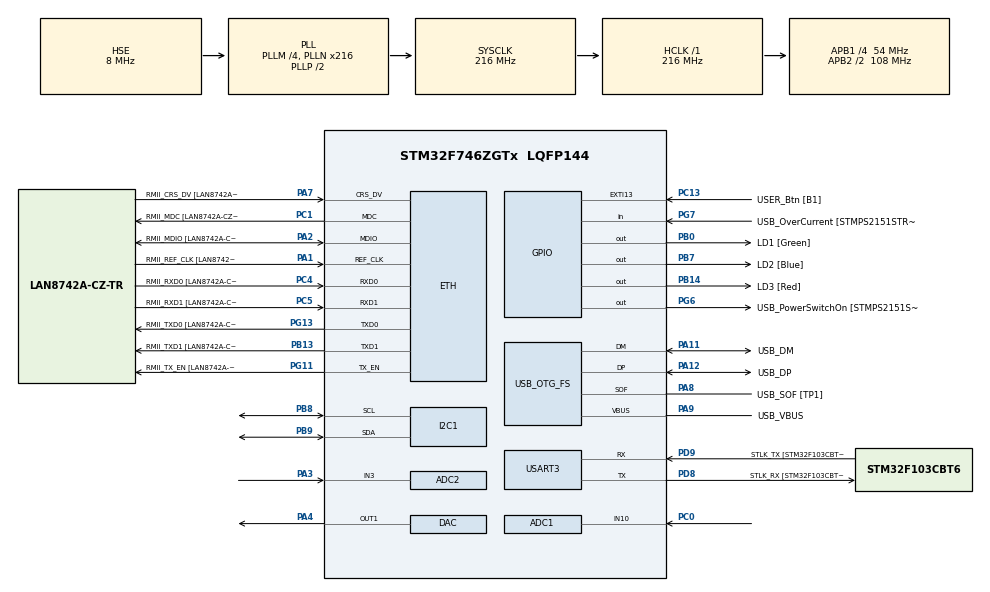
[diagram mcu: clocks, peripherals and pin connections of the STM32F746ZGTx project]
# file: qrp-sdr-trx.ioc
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ADC1.Channel-0\#ChannelRegularConversion=ADC_CHANNEL_10
ADC1.DMAContinuousRequests=ENABLE
ADC1.ExternalTrigConv=ADC_EXTERNALTRIGCONV_T6_TRGO
ADC1.NbrOfConversionFlag=1
ADC1.Rank-0\#ChannelRegularConversion=1
ADC1.SamplingTime-0\#ChannelRegularConversion=ADC_SAMPLETIME_3CYCLES
ADC1.master=1
ADC2.Channel-0\#ChannelRegularConversion=ADC_CHANNEL_3
ADC2.DMAContinuousRequests=ENABLE
ADC2.ExternalTrigConv=ADC_EXTERNALTRIGCONV_T6_TRGO
ADC2.NbrOfConversionFlag=1
ADC2.Rank-0\#ChannelRegularConversion=1
ADC2.SamplingTime-0\#ChannelRegularConversion=ADC_SAMPLETIME_3CYCLES
ADC2.master=1
CORTEX_M7.default_mode_Activation=1
DAC.DAC_Trigger=DAC_TRIGGER_T6_TRGO
DAC.DAC_Trigger_Ch2=DAC_TRIGGER_T6_TRGO
DAC.DAC_OutputBuffer_Ch2=DAC_OUTPUTBUFFER_ENABLE
Dma.ADC1.1.Direction=DMA_PERIPH_TO_MEMORY
Dma.ADC1.1.FIFOMode=DMA_FIFOMODE_DISABLE
Dma.ADC1.1.Instance=DMA2_Stream0
Dma.ADC1.1.MemDataAlignment=DMA_MDATAALIGN_HALFWORD
Dma.ADC1.1.MemInc=DMA_MINC_ENABLE
Dma.ADC1.1.Mode=DMA_CIRCULAR
Dma.ADC1.1.PeriphDataAlignment=DMA_PDATAALIGN_HALFWORD
Dma.ADC1.1.PeriphInc=DMA_PINC_DISABLE
Dma.ADC1.1.Priority=DMA_PRIORITY_HIGH
Dma.ADC2.3.Direction=DMA_PERIPH_TO_MEMORY
Dma.ADC2.3.FIFOMode=DMA_FIFOMODE_DISABLE
Dma.ADC2.3.Instance=DMA2_Stream2
Dma.ADC2.3.MemDataAlignment=DMA_MDATAALIGN_HALFWORD
Dma.ADC2.3.MemInc=DMA_MINC_ENABLE
Dma.ADC2.3.Mode=DMA_CIRCULAR
Dma.ADC2.3.PeriphDataAlignment=DMA_PDATAALIGN_HALFWORD
Dma.ADC2.3.PeriphInc=DMA_PINC_DISABLE
Dma.ADC2.3.Priority=DMA_PRIORITY_HIGH
Dma.DAC1.0.Direction=DMA_MEMORY_TO_PERIPH
Dma.DAC1.0.FIFOMode=DMA_FIFOMODE_DISABLE
Dma.DAC1.0.Instance=DMA1_Stream5
Dma.DAC1.0.MemDataAlignment=DMA_MDATAALIGN_HALFWORD
Dma.DAC1.0.MemInc=DMA_MINC_ENABLE
Dma.DAC1.0.Mode=DMA_CIRCULAR
Dma.DAC1.0.PeriphDataAlignment=DMA_PDATAALIGN_HALFWORD
Dma.DAC1.0.PeriphInc=DMA_PINC_DISABLE
Dma.DAC1.0.Priority=DMA_PRIORITY_HIGH
Dma.DAC2.2.Direction=DMA_MEMORY_TO_PERIPH
Dma.DAC2.2.FIFOMode=DMA_FIFOMODE_DISABLE
Dma.DAC2.2.Instance=DMA1_Stream6
Dma.DAC2.2.MemDataAlignment=DMA_MDATAALIGN_HALFWORD
Dma.DAC2.2.MemInc=DMA_MINC_ENABLE
Dma.DAC2.2.Mode=DMA_CIRCULAR
Dma.DAC2.2.PeriphDataAlignment=DMA_PDATAALIGN_HALFWORD
Dma.DAC2.2.PeriphInc=DMA_PINC_DISABLE
Dma.DAC2.2.Priority=DMA_PRIORITY_HIGH
Dma.Request0=DAC1
Dma.Request1=ADC1
Dma.Request2=DAC2
Dma.Request3=ADC2
ETH.MediaInterface=HAL_ETH_RMII_MODE
ETH.PHY_Name=LAN8742A_PHY_ADDRESS
ETH.PHY_Value=0
ETH.PhyAddress=0
I2C1.Timing=0x20404768
Mcu.Family=STM32F7
Mcu.Name=STM32F746ZGTx
Mcu.Package=LQFP144
NVIC.DMA1_Stream5_IRQn=true\:0\:0\:false\:false\:true\:false\:true\:true
NVIC.DMA1_Stream6_IRQn=true\:0\:0\:false\:false\:true\:false\:true\:true
NVIC.DMA2_Stream0_IRQn=true\:0\:0\:false\:false\:true\:false\:true\:true
NVIC.DMA2_Stream2_IRQn=true\:0\:0\:false\:false\:true\:false\:true\:true
NVIC.PriorityGroup=NVIC_PRIORITYGROUP_4
PA1.GPIO_Label=RMII_REF_CLK [LAN8742A-CZ-TR_REFCLK0]
PA1.Mode=RMII
PA1.Signal=ETH_REF_CLK
PA10.GPIO_Label=USB_ID
PA10.Signal=USB_OTG_FS_ID
PA11.GPIO_Label=USB_DM
PA11.Mode=Device_Only
PA11.Signal=USB_OTG_FS_DM
PA12.GPIO_Label=USB_DP
PA12.Mode=Device_Only
PA12.Signal=USB_OTG_FS_DP
PA13.GPIO_Label=TMS
PA13.Mode=Serial_Wire
PA13.Signal=SYS_JTMS-SWDIO
PA14.GPIO_Label=TCK
PA14.Mode=Serial_Wire
PA14.Signal=SYS_JTCK-SWCLK
PA2.GPIO_Label=RMII_MDIO [LAN8742A-CZ-TR_MDIO]
PA2.Mode=RMII
PA2.Signal=ETH_MDIO
PA3.Signal=ADCx_IN3
PA4.Signal=COMP_DAC1_group
PA5.Signal=DAC_OUT2
PC0.Signal=ADCx_IN10
PA7.GPIO_Label=RMII_CRS_DV [LAN8742A-CZ-TR_CRS_DV]
PA7.Mode=RMII
PA7.Signal=ETH_CRS_DV
PA8.GPIO_Label=USB_SOF [TP1]
PA8.Mode=Activate_SOF_FS
PA8.Signal=USB_OTG_FS_SOF
PA9.GPIO_Label=USB_VBUS
PA9.Mode=Activate_VBUS
PA9.Signal=USB_OTG_FS_VBUS
PB0.GPIO_Label=LD1 [Green]
PB0.Signal=GPIO_Output
PB13.GPIO_Label=RMII_TXD1 [LAN8742A-CZ-TR_TXD1]
PB13.Mode=RMII
PB13.Signal=ETH_TXD1
PB14.GPIO_Label=LD3 [Red]
PB14.Signal=GPIO_Output
PB3.GPIO_Label=SW0
PB3.Signal=SYS_JTDO-SWO
PB7.GPIO_Label=LD2 [Blue]
PB7.Signal=GPIO_Output
PB8.Mode=I2C
PB8.Signal=I2C1_SCL
PB9.Mode=I2C
PB9.Signal=I2C1_SDA
PC1.GPIO_Label=RMII_MDC [LAN8742A-CZ-TR_MDC]
PC1.Mode=RMII
PC1.Signal=ETH_MDC
PC13.GPIO_Label=USER_Btn [B1]
PC13.Signal=GPXTI13
PC14/OSC32_IN.Mode=LSE-External-Oscillator
PC14/OSC32_IN.Signal=RCC_OSC32_IN
PC15/OSC32_OUT.Mode=LSE-External-Oscillator
PC15/OSC32_OUT.Signal=RCC_OSC32_OUT
PC4.GPIO_Label=RMII_RXD0 [LAN8742A-CZ-TR_RXD0]
PC4.Mode=RMII
PC4.Signal=ETH_RXD0
PC5.GPIO_Label=RMII_RXD1 [LAN8742A-CZ-TR_RXD1]
PC5.Mode=RMII
PC5.Signal=ETH_RXD1
PD8.GPIO_Label=STLK_RX [STM32F103CBT6_PA3]
PD8.GPIO_PuPd=GPIO_PULLUP
PD8.Mode=Asynchronous
PD8.Signal=USART3_TX
PD9.GPIO_Label=STLK_TX [STM32F103CBT6_PA2]
PD9.GPIO_PuPd=GPIO_PULLUP
PD9.Mode=Asynchronous
PD9.Signal=USART3_RX
PG11.GPIO_Label=RMII_TX_EN [LAN8742A-CZ-TR_TXEN]
PG11.Mode=RMII
PG11.Signal=ETH_TX_EN
PG13.GPIO_Label=RMII_TXD0 [LAN8742A-CZ-TR_TXD0]
PG13.Mode=RMII
PG13.Signal=ETH_TXD0
PG6.GPIO_Label=USB_PowerSwitchOn [STMPS2151STR_EN]
PG6.Signal=GPIO_Output
PG7.GPIO_Label=USB_OverCurrent [STMPS2151STR_FAULT]
PG7.Signal=GPIO_Input
PH0/OSC_IN.GPIO_Label=MCO [STM32F103CBT6_PA8]
PH0/OSC_IN.Mode=HSE-External-Oscillator
PH0/OSC_IN.Signal=RCC_OSC_IN
PH1/OSC_OUT.Mode=HSE-External-Oscillator
PH1/OSC_OUT.Signal=RCC_OSC_OUT
ProjectManager.HeapSize=0x200
ProjectManager.StackSize=0x400
ProjectManager.TargetToolchain=Makefile
RCC.48MHZClocksFreq_Value=24000000
RCC.AHBFreq_Value=216000000
RCC.APB1CLKDivider=RCC_HCLK_DIV4
RCC.APB1Freq_Value=54000000
RCC.APB1TimFreq_Value=108000000
RCC.APB2CLKDivider=RCC_HCLK_DIV2
RCC.APB2Freq_Value=108000000
RCC.APB2TimFreq_Value=216000000
RCC.CortexFreq_Value=216000000
RCC.HCLKFreq_Value=216000000
RCC.HSE_VALUE=8000000
RCC.HSI_VALUE=16000000
RCC.PLL48CLockSelection=RCC_CLK48SOURCE_PLLSAIP
RCC.PLLM=4
RCC.PLLMUL=RCC_PLL_MUL9
RCC.PLLN=216
RCC.PLLQ=3
RCC.PLLSAIP=RCC_PLLSAIP_DIV8
RCC.PRESCALERUSB=RCC_USBCLKSOURCE_PLL_DIV1_5
RCC.SYSCLKFreq_VALUE=216000000
RCC.SYSCLKSource=RCC_SYSCLKSOURCE_PLLCLK
RCC.SYSCLKSourceVirtual=RCC_SYSCLKSOURCE_PLLCLK
RCC.USBFreq_Value=48000000
RCC.VCOOutputFreq_Value=432000000
SH.ADCx_IN3.0=ADC2_IN3,IN3
SH.ADCx_IN10.0=ADC1_IN10,IN10
SH.COMP_DAC1_group.0=DAC_OUT1,DAC_OUT1
TIM6.Period=49
TIM6.Prescaler=44
TIM6.TIM_MasterOutputTrigger=TIM_TRGO_UPDATE
USART3.VirtualMode-Asynchronous=VM_ASYNC
USB_OTG_FS.VirtualMode=Device_Only
VP_TIM6_VS_ClockSourceINT.Mode=Enable_Timer
board=NUCLEO-F746ZG

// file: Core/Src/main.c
/* USER CODE BEGIN Header */
/**
  ******************************************************************************
  * @file           : main.c
  * @brief          : Main program body
  ******************************************************************************
  * @attention
  *
  * Copyright (c) 2026 STMicroelectronics.
  * All rights reserved.
  *
  * This software is licensed under terms that can be found in the LICENSE file
  * in the root directory of this software component.
  * If no LICENSE file comes with this software, it is provided AS-IS.
  *
  ******************************************************************************
  */
/* USER CODE END Header */
#include "main.h"
#include "string.h"
#include <stdlib.h>

/* USER CODE BEGIN Includes */
#include "stm32f7xx.h"      // <-- MÅ være først
#include "arm_math.h"       // <-- CMSIS-DSP
#include "dsp.h"            // <-- dine DSP-typer
#include "freedv_chain.h"   // <-- FreeDV 1600 RX-kjede
#include "oled.h"
#include "encoder.h"
#include "buttons.h"
#include "hmi.h"
#include "cw_paddle.h"
#include "usb_device.h"
#include "usbd_audio_duplex.h"
#include <math.h>
#include <stdio.h>

/* USER CODE END Includes */

/* USER CODE BEGIN PM */
#define TWO_PI 6.28318530718f
/*
 * Block size is per mode, so the buffers are allocated for the largest case and
 * the DMA is restarted with the size the current mode wants.
 *
 * FreeDV: half a buffer is 1920 samples = 40 ms, and 1920/6 = 320, which is
 * exactly one FDMDV frame. That makes every block cost the same instead of
 * alternating cheap/expensive, which is what it takes to stay real time.
 *
 * FreeDV 2400B: 96 bits at 4800 baud, so 1920 samples at 48 kHz, the same 40 ms
 * as 1600. Its modem is already at 48 kHz, so unlike 1600 there is no
 * resampling on the way in.
 *
 * Analog: 256 samples = 5.3 ms. SSB, AM and NBFM do not care much, but CW
 * break-in does, and 40 ms of round trip delay is very audible on a key.
 */
#define BLOCK_SIZE_MAX     3840
#define BLOCK_SIZE_FREEDV  3840
#define BLOCK_SIZE_2400B   3840
#define BLOCK_SIZE_700D    3840
#define BLOCK_SIZE_700E    3840
#define BLOCK_SIZE_ANALOG   512

// Active size, swapped by radio_set_mode(). Buffers stay BLOCK_SIZE_MAX.
static volatile uint32_t block_size = BLOCK_SIZE_FREEDV;
/* USER CODE END PM */

#if defined ( __ICCARM__ ) /*!< IAR Compiler */
#pragma location=0x2004c000
ETH_DMADescTypeDef  DMARxDscrTab[ETH_RX_DESC_CNT]; /* Ethernet Rx DMA Descriptors */
#pragma location=0x2004c0a0
ETH_DMADescTypeDef  DMATxDscrTab[ETH_TX_DESC_CNT]; /* Ethernet Tx DMA Descriptors */

#elif defined ( __CC_ARM )  /* MDK ARM Compiler */

__attribute__((at(0x2004c000))) ETH_DMADescTypeDef  DMARxDscrTab[ETH_RX_DESC_CNT]; /* Ethernet Rx DMA Descriptors */
__attribute__((at(0x2004c0a0))) ETH_DMADescTypeDef  DMATxDscrTab[ETH_TX_DESC_CNT]; /* Ethernet Tx DMA Descriptors */

#elif defined ( __GNUC__ ) /* GNU Compiler */

ETH_DMADescTypeDef DMARxDscrTab[ETH_RX_DESC_CNT] __attribute__((section(".RxDecripSection"))); /* Ethernet Rx DMA Descriptors */
ETH_DMADescTypeDef DMATxDscrTab[ETH_TX_DESC_CNT] __attribute__((section(".TxDecripSection")));   /* Ethernet Tx DMA Descriptors */
#endif

ETH_TxPacketConfig TxConfig;

ADC_HandleTypeDef hadc1;   /* RX: IF in, PC0 */
DMA_HandleTypeDef hdma_adc1;

ADC_HandleTypeDef hadc2;   /* TX: mic in, PA3 */
DMA_HandleTypeDef hdma_adc2;

DAC_HandleTypeDef hdac;
DMA_HandleTypeDef hdma_dac1;   /* RX: audio out, PA4 (DAC_OUT1) */
DMA_HandleTypeDef hdma_dac2;   /* TX: IF out, PA5 (DAC_OUT2) */

ETH_HandleTypeDef heth;

I2C_HandleTypeDef hi2c1;

TIM_HandleTypeDef htim6;

UART_HandleTypeDef huart3;

PCD_HandleTypeDef hpcd_USB_OTG_FS;

/* USER CODE BEGIN PV */

/*
 * The ADC DMA buffer doubles as the input FIFO for the buffered modes, so it
 * is deeper than one block: five blocks, i.e. 200 ms at 48 kHz. The DMA writes
 * into it continuously and the DSP reads behind, which decouples processing
 * time from the block period without a second copy of the data. Halfword
 * samples because the ADC is 12-bit.
 */
#define ADC_RING_BLOCKS 4
#define ADC_RING_LEN    (ADC_RING_BLOCKS * (BLOCK_SIZE_MAX / 2))

/*
 * Transmit DAC buffer, three blocks deep. In the buffered (FreeDV) modes the
 * DMA plays through it continuously while the main loop encodes and fills
 * ahead, so a 53 ms OFDM encode draws down the cushion instead of stalling the
 * output. The analog modes keep using the first block_size of it as a simple
 * double buffer.
 */
#define DAC_RING_BLOCKS 4
#define DAC_RING_LEN    (DAC_RING_BLOCKS * (BLOCK_SIZE_MAX / 2))

uint16_t dac_buffer[DAC_RING_LEN] = {0};
uint16_t adc_buffer[ADC_RING_LEN] = {0};

// CW sidetone: DAC_OUT1/PA4 (the RX speaker output) doubles as the TX
// sidetone during CW, same as [[cw-design-decisions]] always intended -
// keying is heard through the speaker/phones while DAC_OUT2 carries the
// actual IF out. Only driven (DMA started) when tx_active && MODE_CW; see
// audio_dma_start(). Sized for CW's block size, not the deep DAC_RING_LEN
// ring - CW is always the shallow non-buffered path (mode_cfg[MODE_CW] is
// BLOCK_SIZE_ANALOG, buffered=0), so anything bigger is just wasted static
// RAM, at exactly the size that matters for the heap FreeDV 700D needs.
uint16_t sidetone_buffer[BLOCK_SIZE_ANALOG] = {0};

volatile uint8_t block_ready = 0; // 0: no block ready, 1: first half ready, 2: second half ready
volatile uint8_t dac_block_processing = 0; // 0: not processing, 1: processing

int freedv_ok = 0;          // set once freedv_chain_init() has succeeded

// RX telemetry, printed once a second over the ST-Link VCP
volatile uint32_t rx_blocks = 0;   // blocks through process_block()
volatile float    rx_peak   = 0.0f; // peak |audio| at the modem input
volatile float    rx_rms    = 0.0f; // rms of the same, to judge peak/rms
volatile float    rx_env_min = 0.0f; // AM: smallest envelope value in the block
volatile float    rx_env_avg = 0.0f; // AM: mean envelope, i.e. the carrier level
volatile float    rx_adc_peak = 0.0f; // peak |ADC| before any filtering
volatile uint32_t rx_cycles_max = 0;  // worst-case cycles for one block
volatile uint32_t rx_fdv_cycles_max = 0; // worst-case cycles inside the FreeDV chain
volatile uint32_t rx_adc_cycles = 0;     // TX: worst-case encode cycles
volatile uint32_t tx_cushion_min = 999999; // TX: smallest DAC lead, in samples
static   uint32_t last_report = 0;
static   int      debug_on    = 0;   // continuous telemetry print, off by default

// DWT cycle counter, used to measure how much of each block period the DSP
// actually consumes. One block is block_size/2 samples at 48 kHz.
static void cyclecount_init(void)
{
    CoreDebug->DEMCR |= CoreDebug_DEMCR_TRCENA_Msk;

    // Cortex-M7 gates the DWT registers behind the lock access register; without
    // this CYCCNT stays at 0 and every measurement reads back as zero.
    DWT->LAR = 0xC5ACCE55;

    DWT->CYCCNT = 0;
    DWT->CTRL  |= DWT_CTRL_CYCCNTENA_Msk;
}
nco_t nco;

// NCO for IF-mixing
nco_t nco_if;

// Pre-demod IF-filter (kompleks, men vi bruker samme koeff for I og Q)
arm_fir_instance_f32 pre_demod_filter;

/*

FIR filter designed with
http://t-filter.appspot.com

sampling frequency: 48000 Hz

* 0 Hz - 4000 Hz
  gain = 1
  desired ripple = 0.1 dB
  actual ripple = 0.06811726811384558 dB

* 6000 Hz - 24000 Hz
  gain = 0
  desired attenuation = -60 dB
  actual attenuation = -60.68801081580469 dB

*/

#define PRE_DEMOD_TAPS 73

static float pre_demod_coeffs[PRE_DEMOD_TAPS] = {
  -0.0004930375303321366,
  0.0001064813438661428,
  0.0005748457570259578,
  0.0011898445128213748,
  0.0016502280581233504,
  0.001605207031383133,
  0.000831446560674343,
  -0.0005973708354363059,
  -0.002228627696676951,
  -0.0033377455060532744,
  -0.0032076016149152073,
  -0.0014978471407907723,
  0.001459284866735388,
  0.004620535335059582,
  0.00653528877009168,
  0.0059370991846072535,
  0.00240691382833557,
  -0.003197318174051976,
  -0.008810233649088216,
  -0.0118211865758766,
  -0.010154929160148466,
  -0.003367069515417546,
  0.006744477803887592,
  0.016400388788851774,
  0.021048898446146783,
  0.017199001020187076,
  0.0042202354750242735,
  -0.014651068016007818,
  -0.032657469215897225,
  -0.04131750763191529,
  -0.03320662673344374,
  -0.004808839248635039,
  0.04161063532888555,
  0.09790380688954856,
  0.1519161665559878,
  0.1908448312364271,
  0.20501884795915196,
  0.1908448312364271,
  0.1519161665559878,
  0.09790380688954856,
  0.04161063532888555,
  -0.004808839248635039,
  -0.03320662673344374,
  -0.04131750763191529,
  -0.032657469215897225,
  -0.014651068016007818,
  0.0042202354750242735,
  0.017199001020187076,
  0.021048898446146783,
  0.016400388788851774,
  0.006744477803887592,
  -0.003367069515417546,
  -0.010154929160148466,
  -0.0118211865758766,
  -0.008810233649088216,
  -0.003197318174051976,
  0.00240691382833557,
  0.0059370991846072535,
  0.00653528877009168,
  0.004620535335059582,
  0.001459284866735388,
  -0.0014978471407907723,
  -0.0032076016149152073,
  -0.0033377455060532744,
  -0.002228627696676951,
  -0.0005973708354363059,
  0.000831446560674343,
  0.001605207031383133,
  0.0016502280581233504,
  0.0011898445128213748,
  0.0005748457570259578,
  0.0001064813438661428,
  -0.0004930375303321366
};

/*
 * Scratch shared by ssb_process_block() and nbfm_process_block().
 *
 * process_block() dispatches to exactly one of them, so they are never live at
 * the same time and there is no reason for each to hold its own statics. Both
 * also used to over-allocate: the interleaved buffers only ever index up to
 * 2*n, and the real buffers up to n, where n = BLOCK_SIZE/2.
 *
 * Layout is 10*n floats, which is what nbfm needs (4 real + 3 interleaved);
 * ssb uses 9*n of it. Keeping these separate is what made BLOCK_SIZE 3840
 * overflow RAM.
 */
#define SCRATCH_N (BLOCK_SIZE_MAX / 2)
static float dsp_scratch[10 * SCRATCH_N];

/*
 * CW audio filter: three identical biquad band-pass sections at the tone pitch.
 *
 * Biquads rather than a FIR because pitch and bandwidth are meant to become
 * front panel controls. Retuning this is five coefficients; a FIR with the
 * same skirts would be hundreds of taps to redesign on every turn of a knob.
 * cw_bpf_retune() below is that front-panel-control path, wired up 2026-08-03.
 *
 * Each section is deliberately wider than the target: cascading three narrows
 * the result, so Q 1.42 per section gives about 250 Hz overall. Going much
 * below that starts to ring and smears the elements at speed, which reads
 * worse than a wider filter.
 */
#define CW_PITCH_DEFAULT_HZ  700.0f
#define CW_PITCH_MIN_HZ      300.0f
#define CW_PITCH_MAX_HZ     1000.0f
#define CW_FILTER_Q           1.42f
#define CW_STAGES     3

// Runtime pitch: also what the TX carrier offsets from the IF centre by
// (see cw_tx_restart()), so RX filter and TX sidetone stay one linked
// setting rather than drifting apart - the design principle from
// [[cw-design-decisions]].
float cw_pitch_hz = CW_PITCH_DEFAULT_HZ;

// CMSIS's biquad init stores the pointer it's given rather than copying, so
// this has to be static storage, not a stack buffer computed on the fly.
static float cw_coeffs_runtime[5 * CW_STAGES];

arm_biquad_casd_df1_inst_f32 cw_bpf;
static float cw_state[4 * CW_STAGES];

/*
 * (Re)design the CW band-pass filter for a new centre frequency, RBJ
 * "constant skirt gain" band-pass biquad, reverse-derived to match this
 * project's original fixed-700 Hz coefficients (Q 1.42, confirmed by
 * working backward from them to within rounding). Same 5 coefficients in
 * all three cascaded stages, same as the fixed table this replaces.
 */
static void cw_bpf_retune(float pitch_hz)
{
    float w0    = TWO_PI * pitch_hz / 48000.0f;
    float alpha = sinf(w0) / (2.0f * CW_FILTER_Q);
    float a0    = 1.0f + alpha;
    float cosw0 = cosf(w0);

    float b0 =  alpha / a0;
    float b2 = -alpha / a0;
    float a1 =  (2.0f * cosw0) / a0;   /* CMSIS df1 sign convention */
    float a2 = -(1.0f - alpha) / a0;

    for (int s = 0; s < CW_STAGES; s++)
    {
        cw_coeffs_runtime[5*s + 0] = b0;
        cw_coeffs_runtime[5*s + 1] = 0.0f;
        cw_coeffs_runtime[5*s + 2] = b2;
        cw_coeffs_runtime[5*s + 3] = a1;
        cw_coeffs_runtime[5*s + 4] = a2;
    }

    arm_biquad_cascade_df1_init_f32(&cw_bpf, CW_STAGES, cw_coeffs_runtime, cw_state);
}

/* Clamp and apply a new CW pitch - called from the HMI (Function -> CW
   pitch -> encoder) and available for the console later if wanted. Retunes
   immediately regardless of MODE; harmless when not in CW, since cw_bpf
   just sits unused until MODE_CW reads it. */
void cw_set_pitch(float hz)
{
    if (hz < CW_PITCH_MIN_HZ) hz = CW_PITCH_MIN_HZ;
    if (hz > CW_PITCH_MAX_HZ) hz = CW_PITCH_MAX_HZ;
    cw_pitch_hz = hz;
    cw_bpf_retune(cw_pitch_hz);
}

arm_fir_instance_f32 pre_fm_I;
arm_fir_instance_f32 pre_fm_Q;

static float pre_fm_state_I[PRE_DEMOD_TAPS + BLOCK_SIZE_MAX/2];
static float pre_fm_state_Q[PRE_DEMOD_TAPS + BLOCK_SIZE_MAX/2];

/* USER CODE END PV */

void SystemClock_Config(void);
static void MPU_Config(void);
static void MX_GPIO_Init(void);
static void MX_DMA_Init(void);
static void MX_ETH_Init(void);
static void MX_I2C1_Init(void);
static void MX_USART3_UART_Init(void);
static void MX_USB_OTG_FS_PCD_Init(void);
static void MX_DAC_Init(void);
static void MX_TIM6_Init(void);
static void MX_ADC1_Init(void);
static void MX_ADC2_Init(void);

/* USER CODE BEGIN 0 */

/*
 * USART3 is wired to the ST-Link virtual COM port (/dev/ttyACM0), 115200 8N1.
 *
 * Queued rather than sent with HAL_UART_Transmit, which blocks: a 123 character
 * telemetry line takes 10.7 ms at 115200, and the analog block period is
 * 5.3 ms, so every report used to cost two blocks of audio. Here uart_puts()
 * only appends and uart_pump() moves one byte per main loop pass, which is
 * ample when the loop turns over hundreds of thousands of times a second.
 */
#define TX_RING 512   /* power of two */

static char              tx_ring[TX_RING];
static volatile uint16_t tx_wr, tx_rd;

static void uart_pump(void)
{
    if (tx_rd != tx_wr && (huart3.Instance->ISR & USART_ISR_TXE))
        huart3.Instance->TDR = tx_ring[tx_rd++ & (TX_RING - 1)];
}

/* uart_pump() above only moves one byte per main-loop pass - fine for
   telemetry, but useless for a diagnostic printed right before a crash that
   never returns to the main loop. Blocks until the whole ring is actually
   on the wire, not just queued. Exported for codec2_alloc_report_fail() in
   freedv_chain.c, the one caller that needs a guarantee, not a best effort. */
void uart_flush_blocking(void)
{
    while (tx_rd != tx_wr)
    {
        while (!(huart3.Instance->ISR & USART_ISR_TXE)) { }
        huart3.Instance->TDR = tx_ring[tx_rd++ & (TX_RING - 1)];
    }
}

void uart_puts(const char *s)
{
    while (*s)
    {
        /* Only ever blocks if the queue backs up, which startup can do. */
        while ((uint16_t)(tx_wr - tx_rd) >= TX_RING)
            uart_pump();

        tx_ring[tx_wr++ & (TX_RING - 1)] = *s++;
    }
}

// Integer-only formatting on purpose: printf("%f") needs -u _printf_float,
// which nano.specs leaves out.
static void uart_kv(const char *key, int value)
{
    char buf[48];
    char *p = buf;
    int   n = value;
    int   digits = 0;
    char  tmp[12];

    while (*key)
        *p++ = *key++;
    *p++ = '=';

    if (n < 0) { *p++ = '-'; n = -n; }
    do { tmp[digits++] = '0' + (n % 10); n /= 10; } while (n);
    while (digits)
        *p++ = tmp[--digits];

    *p++ = ' ';
    *p   = '\0';

    uart_puts(buf);
}

// If block_ready is still set when the next half completes, the main loop did
// not keep up and a block of samples is lost. FreeDV cannot tolerate that: the
// modem needs an unbroken sample stream to hold sync.
volatile uint32_t rx_overruns = 0;

/*
 * Read position into the ADC ring. The DMA controller is the writer and its
 * position is the transfer counter, so nothing has to be tracked in an ISR.
 * The ring is a whole number of blocks, so a block read never wraps.
 *
 * Half duplex, so exactly one ADC and one DAC channel is ever running:
 * hadc1/DAC_OUT1 (IF in / audio out) on RX, hadc2/DAC_OUT2 (mic in / IF out)
 * on TX. tx_active picks which pair's DMA position is live.
 */
extern volatile int tx_active;

static uint32_t adc_rd;

static uint32_t adc_dma_pos(void)
{
    ADC_HandleTypeDef *adc = tx_active ? &hadc2 : &hadc1;
    return ADC_RING_LEN - __HAL_DMA_GET_COUNTER(adc->DMA_Handle);
}

static uint32_t dac_dma_pos(void)
{
    DMA_HandleTypeDef *dma = tx_active ? hdac.DMA_Handle2 : hdac.DMA_Handle1;
    return DAC_RING_LEN - __HAL_DMA_GET_COUNTER(dma);
}

static uint32_t adc_avail(void)
{
    uint32_t w = adc_dma_pos();
    return (w >= adc_rd) ? (w - adc_rd) : (ADC_RING_LEN - adc_rd + w);
}

extern int MODE;                 /* defined further down, with the mode list */
int mode_is_buffered(int mode);

void HAL_ADC_ConvHalfCpltCallback(ADC_HandleTypeDef *hadc)
{
    if (mode_is_buffered(MODE)) return;   /* the DSP reads the ring directly */

    if (block_ready) rx_overruns++;
    block_ready = 1;
}

void HAL_ADC_ConvCpltCallback(ADC_HandleTypeDef *hadc)
{
    if (mode_is_buffered(MODE)) return;   /* the DSP reads the ring directly */

    if (block_ready) rx_overruns++;
    block_ready = 2;
}

void HAL_DAC_ConvHalfCpltCallbackCh1(DAC_HandleTypeDef *hdac)
{
    // DAC half conversion complete callback (channel 1)
    // You can add code here if needed
    dac_block_processing = 1;
}

void HAL_DAC_ConvCpltCallbackCh1(DAC_HandleTypeDef *hdac)
{
    // DAC conversion complete callback (channel 1)
    // You can add code here if needed
    dac_block_processing = 2;
}

/*
 * Channel 2 (TX IF out) mirrors channel 1: dac_block_processing is what
 * paces tx_process_block() in the main loop, and on TX it is channel 2 that
 * is actually running the DMA, not channel 1.
 */
void HAL_DACEx_ConvHalfCpltCallbackCh2(DAC_HandleTypeDef *hdac)
{
    dac_block_processing = 1;
}

void HAL_DACEx_ConvCpltCallbackCh2(DAC_HandleTypeDef *hdac)
{
    dac_block_processing = 2;
}

/*
//Hilbert filter for SSB
#define HILBERT_TAPS 63

static float hilbert_coeffs[HILBERT_TAPS] = {
    -0.0041, -0.0037, -0.0028, -0.0014, 0.0004, 0.0025, 0.0047,
    0.0067, 0.0082, 0.0089, 0.0086, 0.0071, 0.0044, 0.0007,
    -0.0034, -0.0076, -0.0114, -0.0143, -0.0158, -0.0156,
    -0.0135, -0.0096, -0.0043, 0.0020, 0.0087, 0.0151,
    0.0204, 0.0239, 0.0251, 0.0239, 0.0204, 0.0151,
    0.0087, 0.0020, -0.0043, -0.0096, -0.0135, -0.0156,
    -0.0158, -0.0143, -0.0114, -0.0076, -0.0034, 0.0007,
    0.0044, 0.0071, 0.0086, 0.0089, 0.0082, 0.0067,
    0.0047, 0.0025, 0.0004, -0.0014, -0.0028, -0.0037,
    -0.0041
};
*/

//Hilbert filter for NBFM
/*

FIR filter designed with
http://t-filter.appspot.com

sampling frequency: 48000 Hz

* 0 Hz - 6000 Hz
  gain = 0
  desired attenuation = -60 dB
  actual attenuation = -50.41488654693752 dB

* 8000 Hz - 16000 Hz
  gain = 1
  desired ripple = 5 dB
  actual ripple = 15.449541453020096 dB

* 18000 Hz - 24000 Hz
  gain = 0
  desired attenuation = -60 dB
  actual attenuation = -50.41488654693752 dB

*/

#define HILBERT_TAPS 17

static float hilbert_coeffs[HILBERT_TAPS] = {
  0.02352204878641468,
  -7.964549159078516e-16,
  -0.094806149454076,
  5.916427478655016e-16,
  0.21352320600109478,
  -7.4996177568773785e-16,
  -0.3325693585500034,
  4.3317065620714974e-17,
  0.3830170947566392,
  4.3317065620714974e-17,
  -0.3325693585500034,
  -7.4996177568773785e-16,
  0.21352320600109478,
  5.916427478655016e-16,
  -0.094806149454076,
  -7.964549159078516e-16,
  0.02352204878641468
};

static float hilbert_state[HILBERT_TAPS + BLOCK_SIZE_MAX/2];
arm_fir_instance_f32 hilbert;

#define IF_TAPS 101

static float if_coeffs[101] = {
    -0.0003, -0.0004, -0.0005, -0.0006, -0.0007, -0.0008,
    -0.0009, -0.0010, -0.0011, -0.0012, -0.0013, -0.0014,
    -0.0015, -0.0016, -0.0017, -0.0018, -0.0019, -0.0020,
    -0.0021, -0.0022, -0.0023, -0.0024, -0.0025, -0.0026,
    -0.0027, -0.0028, -0.0029, -0.0030, -0.0031, -0.0032,
    -0.0033, -0.0034, -0.0035, -0.0036, -0.0037, -0.0038,
    -0.0039, -0.0040, -0.0041, -0.0042, -0.0043, -0.0044,
    -0.0045, -0.0046, -0.0047, -0.0048, -0.0049, -0.0050,
    0.9950,
    -0.0050, -0.0049, -0.0048, -0.0047, -0.0046, -0.0045,
    -0.0044, -0.0043, -0.0042, -0.0041, -0.0040, -0.0039,
    -0.0038, -0.0037, -0.0036, -0.0035, -0.0034, -0.0033,
    -0.0032, -0.0031, -0.0030, -0.0029, -0.0028, -0.0027,
    -0.0026, -0.0025, -0.0024, -0.0023, -0.0022, -0.0021,
    -0.0020, -0.0019, -0.0018, -0.0017, -0.0016, -0.0015,
    -0.0014, -0.0013, -0.0012, -0.0011, -0.0010, -0.0009,
    -0.0008, -0.0007, -0.0006, -0.0005, -0.0004, -0.0003
};

static float if_state[IF_TAPS + BLOCK_SIZE_MAX/2];
arm_fir_instance_f32 pre_demod_filter;

#define AUDIO_TAPS 63

static float audio_lpf_coeffs[AUDIO_TAPS] = {
    // 3 kHz LPF, 48 kHz fs, Hamming window
    -0.0007, -0.0010, -0.0013, -0.0016, -0.0019, -0.0022,
    -0.0025, -0.0028, -0.0031, -0.0034, -0.0037, -0.0040,
    -0.0043, -0.0046, -0.0049, -0.0052, -0.0055, -0.0058,
    -0.0061, -0.0064, -0.0067, -0.0070, -0.0073, -0.0076,
    -0.0079, -0.0082, -0.0085, -0.0088, -0.0091, -0.0094,
    0.9900,
    -0.0094, -0.0091, -0.0088, -0.0085, -0.0082, -0.0079,
    -0.0076, -0.0073, -0.0070, -0.0067, -0.0064, -0.0061,
    -0.0058, -0.0055, -0.0052, -0.0049, -0.0046, -0.0043,
    -0.0040, -0.0037, -0.0034, -0.0031, -0.0028, -0.0025,
    -0.0022, -0.0019, -0.0016, -0.0013, -0.0010, -0.0007
};

static float audio_state[AUDIO_TAPS + BLOCK_SIZE_ANALOG/2];
arm_fir_instance_f32 audio_lpf;

#define MODE_NBFM 0
#define MODE_USB  1
#define MODE_LSB  2
#define MODE_FREEDV 3   // FreeDV 1600, received as USB
#define MODE_FREEDV_2400B 4  // FreeDV 2400B, through a normal FM audio path
#define MODE_FREEDV_700D  5  // FreeDV 700D, OFDM + LDPC on SSB for weak signals
#define MODE_FREEDV_700E  6  // FreeDV 700E, shorter frame than 700D, faster reacquire
#define MODE_AM           7  // AM, envelope detection off the complex baseband
#define MODE_CW           8  // CW, SSB demod into a narrow filter at the tone pitch

int MODE = MODE_USB;  // default mode

/*
 * Fill an interleaved cos/sin buffer for the IF mixer.
 *
 * Recursive phasor rotation rather than cosf()/sinf() per sample: two libm
 * calls per sample was one of the larger costs in the block. Magnitude drifts
 * slowly, so it is renormalised once per call instead of per sample.
 */
static void nco_block_iq(float *NCO_buf, int n)
{
    static float osc_re = 1.0f, osc_im = 0.0f;
    static float step_re = 1.0f, step_im = 0.0f;
    static float step_dphi = 0.0f;

    if (step_dphi != nco.dphi)
    {
        step_dphi = nco.dphi;
        step_re   = cosf(nco.dphi);
        step_im   = sinf(nco.dphi);
    }

    for (int i = 0; i < n; i++)
    {
        NCO_buf[2*i + 0] = osc_re;
        NCO_buf[2*i + 1] = osc_im;

        float nre = osc_re * step_re - osc_im * step_im;
        float nim = osc_re * step_im + osc_im * step_re;

        osc_re = nre;
        osc_im = nim;
    }

    float mag2 = osc_re * osc_re + osc_im * osc_im;
    float g    = 1.5f - 0.5f * mag2;   // one Newton step toward 1/sqrt(mag2)

    osc_re *= g;
    osc_im *= g;
}

void ssb_process_block(const uint16_t *in, uint16_t *out, int n)
{
    // Carved out of the shared scratch pool; see dsp_scratch above.
    float *I_buf     = &dsp_scratch[0 * SCRATCH_N];
    float *Q_buf     = &dsp_scratch[1 * SCRATCH_N];
    float *audio_buf = &dsp_scratch[2 * SCRATCH_N];

    float *IQ_in     = &dsp_scratch[3 * SCRATCH_N];   // interleaved I/Q,   2n
    float *NCO_buf   = &dsp_scratch[5 * SCRATCH_N];   // interleaved cos/sin, 2n
    float *IQ_mix    = &dsp_scratch[7 * SCRATCH_N];   // interleaved I/Q,   2n
    float *ssb_raw   = &dsp_scratch[9 * SCRATCH_N];   // FreeDV fallback audio, see MODE_FREEDV below

    // ---------------------------------------------------------
    // 1) ADC → normalisert I
    // ---------------------------------------------------------
    float adc_peak = 0.0f;

    for (int i = 0; i < n; i++)
    {
        uint32_t raw = in[i] & 0x0FFF;
        I_buf[i] = ((float)raw - 2048.0f) / 2048.0f;

        float a = fabsf(I_buf[i]);
        if (a > adc_peak) adc_peak = a;
    }

    rx_adc_peak = adc_peak;

    // ---------------------------------------------------------
    // 2) Hilbert → Q (for SSB og FM)
    // ---------------------------------------------------------
    arm_fir_f32(&hilbert, I_buf, Q_buf, n);

    // ---------------------------------------------------------
    // 3) Lag interleaved I/Q
    // ---------------------------------------------------------
    for (int i = 0; i < n; i++)
    {
        IQ_in[2*i + 0] = I_buf[i];
        IQ_in[2*i + 1] = Q_buf[i];
    }

    // ---------------------------------------------------------
    // 4) NCO → interleaved cos/sin
    // ---------------------------------------------------------
    nco_block_iq(NCO_buf, n);

    // ---------------------------------------------------------
    // 5) Kompleks mixing
    // ---------------------------------------------------------
    arm_cmplx_mult_cmplx_f32(IQ_in, NCO_buf, IQ_mix, n);

    // ---------------------------------------------------------
    // 6) Splitt ut I/Q etter mixing
    // ---------------------------------------------------------
    for (int i = 0; i < n; i++)
    {
        I_buf[i] = IQ_mix[2*i + 0];
        Q_buf[i] = IQ_mix[2*i + 1];
    }

    // ---------------------------------------------------------
    // 7) Pre-demod IF-filter
    // ---------------------------------------------------------
    arm_fir_f32(&pre_fm_I, I_buf, I_buf, n);
    arm_fir_f32(&pre_fm_Q, Q_buf, Q_buf, n);

    // ---------------------------------------------------------
    // 8) MODE-basert demod
    // ---------------------------------------------------------
    if(MODE == MODE_USB)
    {
        // USB = I - Q  (swapped to match how the sideband lands on the air
        // after the up-conversion, confirmed against an FT-857D)
        for (int i = 0; i < n; i++)
            audio_buf[i] = I_buf[i] - Q_buf[i];

        /* Post-demod level, same pattern as the CW branch below - this is
           what the HMI's S-meter reads (hmi.c), so it needs to reflect the
           tuned signal, not just the raw pre-mix ADC swing. */
        float peak = 0.0f, sumsq = 0.0f;
        for (int i = 0; i < n; i++)
        {
            float a = fabsf(audio_buf[i]);
            if (a > peak) peak = a;
            sumsq += audio_buf[i] * audio_buf[i];
        }
        rx_peak = peak;
        rx_rms  = sqrtf(sumsq / (float)n);
        rx_blocks++;
    }
    else if (MODE == MODE_LSB)
    {
        // LSB = I + Q
        for (int i = 0; i < n; i++)
            audio_buf[i] = I_buf[i] + Q_buf[i];

        /* Same reasoning as MODE_USB above. */
        float peak = 0.0f, sumsq = 0.0f;
        for (int i = 0; i < n; i++)
        {
            float a = fabsf(audio_buf[i]);
            if (a > peak) peak = a;
            sumsq += audio_buf[i] * audio_buf[i];
        }
        rx_peak = peak;
        rx_rms  = sqrtf(sumsq / (float)n);
        rx_blocks++;
    }
    else if (MODE == MODE_CW)
    {
        /*
         * CW is just SSB into a narrow filter. Tuning is what places the
         * carrier at the wanted pitch; the filter is centred there rather
         * than at zero, which is why the pitch is a system setting and not
         * simply a bandwidth.
         */
        static agc_t agc_cw = {1.0f};

        for (int i = 0; i < n; i++)
            audio_buf[i] = I_buf[i] + Q_buf[i];

        arm_biquad_cascade_df1_f32(&cw_bpf, audio_buf, audio_buf, n);

        float peak = 0.0f, sumsq = 0.0f;
        for (int i = 0; i < n; i++)
        {
            float a = fabsf(audio_buf[i]);
            if (a > peak) peak = a;
            sumsq += audio_buf[i] * audio_buf[i];
        }
        rx_peak = peak;
        rx_rms  = sqrtf(sumsq / (float)n);
        rx_blocks++;

        /* Slow decay so the gain does not wind up between elements. */
        agc_block_cfg(audio_buf, n, &agc_cw, 0.25f, 0.002f);
    }
    else if (MODE == MODE_FREEDV || MODE == MODE_FREEDV_700D
                                 || MODE == MODE_FREEDV_700E)
    {
        // FreeDV rides on an ordinary SSB signal, so demodulate as USB first.
        float peak = 0.0f, sumsq = 0.0f;

        for (int i = 0; i < n; i++)
        {
            audio_buf[i] = I_buf[i] + Q_buf[i];

            float a = fabsf(audio_buf[i]);
            if (a > peak) peak = a;
            sumsq += audio_buf[i] * audio_buf[i];
        }

        rx_peak = peak;
        rx_rms  = sqrtf(sumsq / (float)n);
        rx_blocks++;

        // Keep the plain-SSB audio so we can fall back to it below - this is
        // what makes "listen on SSB, switch over once FreeDV syncs" work:
        // audio_buf gets overwritten with decoded speech (or noise, while
        // still hunting for sync), so save the version before that happens.
        memcpy(ssb_raw, audio_buf, n * sizeof(float));

        // 48k -> 8k -> FreeDV demod -> 8k -> 48k
        if (freedv_ok)
        {
            uint32_t t0 = DWT->CYCCNT;

            freedv_chain_put_audio48(audio_buf, n);
            freedv_chain_get_speech48(audio_buf, n);

            uint32_t dt = DWT->CYCCNT - t0;
            if (dt > rx_fdv_cycles_max)
                rx_fdv_cycles_max = dt;
        }

        // Not synced yet (or freedv_open() itself failed): play the SSB
        // audio instead of silence/decoder noise, same idea as an analog
        // squelch - you hear the signal you're tuned to either way, just
        // as decoded speech once sync locks.
        if (!freedv_ok || !freedv_chain_synced())
            memcpy(audio_buf, ssb_raw, n * sizeof(float));
    }
    else
    {
        for (int i = 0; i < n; i++)
            audio_buf[i] = 0.0f;
    }

    // ---------------------------------------------------------
    // 9) Audio gain før DAC
    // ---------------------------------------------------------
    for (int i = 0; i < n; i++)
        audio_buf[i] *= 1500.0f;

    // ---------------------------------------------------------
    // 10) DAC output
    // ---------------------------------------------------------
    for (int i = 0; i < n; i++)
    {
        float y = audio_buf[i] + 2048.0f;

        if (y < 0.0f)    y = 0.0f;
        if (y > 4095.0f) y = 4095.0f;

        out[i] = (uint16_t)y;
    }
}

void nbfm_process_block(const uint16_t *in, uint16_t *out, int n)
{
    // Carved out of the shared scratch pool; see dsp_scratch above.
    float *I_if          = &dsp_scratch[0 * SCRATCH_N];
    float *Q_if          = &dsp_scratch[1 * SCRATCH_N];
    float *audio_fm      = &dsp_scratch[2 * SCRATCH_N];   // FM-demod audio
    float *audio_lpf_out = &dsp_scratch[3 * SCRATCH_N];

    float *IQ_in         = &dsp_scratch[4 * SCRATCH_N];   // interleaved I/Q,   2n
    float *NCO_buf       = &dsp_scratch[6 * SCRATCH_N];   // interleaved cos/sin, 2n
    float *IQ_mix        = &dsp_scratch[8 * SCRATCH_N];   // interleaved I/Q,   2n

    // -----------------------------
    // 1) ADC → normalisert IF (I)
    // -----------------------------
    for (int i = 0; i < n; i++)
    {
        uint32_t raw = in[i] & 0x0FFF;
        I_if[i] = ((float)raw - 2048.0f) / 2048.0f;
        //Q_if[i] = 0.0f;   // ren IF, ingen Hilbert her
    }

    arm_fir_f32(&hilbert, I_if, Q_if, n);

    // -----------------------------
    // 2) Lag interleaved I/Q
    // -----------------------------
    for (int i = 0; i < n; i++)
    {
        IQ_in[2*i + 0] = I_if[i];
        IQ_in[2*i + 1] = Q_if[i];
    }

    // -----------------------------
    // 3) NCO → interleaved cos/sin
    // -----------------------------
    for (int i = 0; i < n; i++)
    {
        float cs = cosf(nco_if.phase);
        float sn = sinf(nco_if.phase);
        nco_step(&nco_if);

        NCO_buf[2*i + 0] = cs;
        NCO_buf[2*i + 1] = sn;
    }

    // -----------------------------
    // 4) Kompleks mixing (IF → baseband FM)
    // -----------------------------
    arm_cmplx_mult_cmplx_f32(IQ_in, NCO_buf, IQ_mix, n);

    // -----------------------------
    // 5) Splitt ut I/Q etter mixing
    // -----------------------------
    for (int i = 0; i < n; i++)
    {
        I_if[i] = IQ_mix[2*i + 0];
        Q_if[i] = IQ_mix[2*i + 1];
    }

    // -----------------------------
    // 6) Pre-demod IF-filter (kompleks)
    // -----------------------------
    arm_fir_f32(&pre_fm_I, I_if, I_if, n);
    arm_fir_f32(&pre_fm_Q, Q_if, Q_if, n);

    // -----------------------------
    // 7) FM-demodulator (din nbfm_demod)
    // -----------------------------
    nbfm_demod(I_if, Q_if, audio_fm, n);

    // -----------------------------
    // 8) Audio LPF etter FM-demod
    // -----------------------------
    arm_fir_f32(&audio_lpf, audio_fm, audio_lpf_out, n);

    // Post-demod level for the HMI's S-meter (hmi.c) - same reasoning as
    // ssb_process_block()/freedv2400b_process_block(), this was the one RX
    // mode still missing it.
    {
        float peak = 0.0f, sumsq = 0.0f;
        for (int i = 0; i < n; i++)
        {
            float a = fabsf(audio_lpf_out[i]);
            if (a > peak) peak = a;
            sumsq += audio_lpf_out[i] * audio_lpf_out[i];
        }
        rx_peak = peak;
        rx_rms  = sqrtf(sumsq / (float)n);
        rx_blocks++;
    }

    // -----------------------------
    // 9) Gain + DAC-skalering
    // -----------------------------
    for (int i = 0; i < n; i++)
    {
        float y = audio_lpf_out[i] * 1500.0f + 2048.0f;

        if (y < 0.0f)    y = 0.0f;
        if (y > 4095.0f) y = 4095.0f;

        out[i] = (uint16_t)y;
    }
}

extern float mic_gain;   /* defined with the SSB modulator below */

/*
 * Frequency modulate a ready audio buffer.
 *
 * Deviation is a parameter because voice and data want different values:
 * 5 kHz for speech, but 2.5 kHz for FreeDV 2400B, which is what its
 * demodulator expects and what stops the discriminator running into atan2's
 * wrap point at the far end.
 */
static void fm_modulate(const float *audio, uint16_t *out, int n, float dev_hz)
{
    static float phase = 0.0f;

    const float kf   = 2.0f * (float)M_PI * dev_hz  / 48000.0f;
    const float w_if = 2.0f * (float)M_PI * 12000.0f / 48000.0f;

    for (int i = 0; i < n; i++)
    {
        phase += w_if + kf * audio[i];

        if (phase >  (float)M_PI) phase -= TWO_PI;
        if (phase < -(float)M_PI) phase += TWO_PI;

        out[i] = (uint16_t)((cosf(phase) * 2048.0f) + 2048.0f);
    }
}

void nbfm_tx_process_block(const uint16_t *in, uint16_t *out, int n)
{
    /* Shared with the receive path: transmit and receive never run together. */
    float *audio_in       = &dsp_scratch[0 * SCRATCH_N];
    float *audio_filtered = &dsp_scratch[1 * SCRATCH_N];

    const float dev_hz = 5000.0f;

    float peak = 0.0f;

    for (int i = 0; i < n; i++)
    {
        float x = (((float)(in[i] & 0x0FFF)) - 2048.0f) / 2048.0f;

        float a = fabsf(x);
        if (a > peak) peak = a;

        audio_in[i] = x * mic_gain;
    }

    rx_adc_peak = peak;

    arm_fir_f32(&audio_lpf, audio_in, audio_filtered, n);

    float dpk = 0.0f;
    for (int i = 0; i < n; i++)
    {
        float a = fabsf(audio_filtered[i]);
        if (a > dpk) dpk = a;
    }

    fm_modulate(audio_filtered, out, n, dev_hz);

    rx_peak = dpk * dev_hz / 1000.0f;   /* peak deviation in kHz */
    rx_blocks++;
}

void nbfm_init(float if_freq_hz, float fs_hz);
static void ssb_tx_init(void);
extern volatile int am_testtone;
static void audio_dma_start(void);
static void audio_dma_restart(void);
extern volatile int tx_active;

/*
 * Filters are (re)initialised here rather than inline in main() so a mode
 * change can flush them. The FIR instances are sized for BLOCK_SIZE_MAX;
 * calling them later with a smaller block is safe, the state buffer is simply
 * bigger than that call needs.
 */
static void dsp_filters_init(void)
{
    // ssb_process_block() mixes with 'nco', not the 'nco_if' that nbfm_init()
    // sets up, so it needs its own init or dphi stays 0 and nothing is
    // downconverted.
    nco_init(&nco, 12000.0f, 48000.0f);

    // NCO for the FM path, plus pre_fm_I/Q and the post-demod audio LPF.
    nbfm_init(12000.0f, 48000.0f);

    ssb_tx_init();

    cw_bpf_retune(cw_pitch_hz);   /* re-apply the current pitch, not the 700 Hz default */

    // Hilbert for SSB
    arm_fir_init_f32(&hilbert,
                     HILBERT_TAPS,
                     hilbert_coeffs,
                     hilbert_state,
                     BLOCK_SIZE_MAX/2);

}

// The DAC idles at mid-scale; zero would slam the output to the rail.
#define DAC_MID 2048

/*
 * Audio routing: normally TX mic-in/RX speaker-out ride the real ADC2/DAC1
 * analog pins. SRC_USB instead ties the same process_block()/
 * tx_process_block() call sites to the USBD_AUDIO_DUPLEX class (see
 * usbd_audio_duplex.c) - PC speaker audio substitutes for the mic ADC
 * samples on TX, and RX DAC audio is mirrored out to the PC as "microphone"
 * input instead of/in addition to the physical DAC1 pin. Chosen once by
 * the operator (console "src" command / HMI menu), not mixed at runtime -
 * simpler than blending two sources, and each is independently testable.
 */
typedef enum { AUDIO_SRC_ANALOG = 0, AUDIO_SRC_USB } audio_src_t;
volatile audio_src_t audio_source = AUDIO_SRC_ANALOG;

/* uint16 ADC/DAC samples here are 12-bit, DC-centered at DAC_MID (2048).
   USB Audio PCM is 16-bit signed, centered at 0. <<4 covers the 12->16 bit
   range exactly (2048 << 4 = 32768). */
static inline int16_t sample_to_pcm16(uint16_t raw)
{
    int32_t v = ((int32_t)raw - DAC_MID) << 4;
    if (v >  32767) v =  32767;
    if (v < -32768) v = -32768;
    return (int16_t)v;
}

static inline uint16_t pcm16_to_sample(int16_t pcm)
{
    int32_t v = DAC_MID + ((int32_t)pcm >> 4);
    if (v < 0)    v = 0;
    if (v > 4095) v = 4095;
    return (uint16_t)v;
}

/* Call right before a TX process_block()/tx_process_block() reads its ADC
   slice: when SRC_USB, overwrite that slice with PC "speaker" audio pulled
   from the USB class instead, so the mode's DSP is none the wiser about
   where its input came from. */
extern float mic_gain;   /* defined with the SSB modulator below */

/*
 * Returns the buffer the TX modulator should actually read this block:
 * normally the caller's own ADC slice, but a private buffer holding USB
 * audio when SRC_USB.
 *
 * It must NOT write into adc_buffer. ADC2's DMA runs continuously into
 * that buffer during transmit (audio_dma_start(): HAL_ADC_Start_DMA(&hadc2,
 * adc_buffer, ...) in circular mode), paced by the same TIM6 as the DAC -
 * so anything written there is racing live mic samples landing in the very
 * same half at 48 kHz. Some injected samples survived to the modulator,
 * others were overwritten by (near-silent) mic data first, at a cadence
 * tied to the DMA position: audible as chopped-up audio, while every USB
 * ring counter stayed perfectly clean because the ring itself was never
 * the problem - the corruption happened downstream, after the handoff.
 * Analog TX was unaffected for the same reason: no injection, the ADC data
 * is exactly what that path wants.
 */
/*
 * Bisection aid for the "USB TX audio sounds chopped" hunt: when set (the
 * console's "tone" command), a clean firmware-generated 1 kHz sine is fed
 * to the modulator INSTEAD of the USB audio, entering the TX chain at
 * exactly the same point with exactly the same scaling. Everything
 * downstream - modulator, DAC, DMA, RF - is identical either way, so:
 *   tone clean, USB chopped  -> the samples arriving over USB are already
 *                               chopped before we touch them (host side)
 *   tone also chopped        -> something in this firmware's TX handling
 *                               of injected audio, not the USB transport
 * Analog TX being clean already rules the modulator itself out, but it
 * reads adc_buffer directly and never exercises this injection path.
 */
volatile int usb_tx_testtone = 0;

static const uint16_t *usb_audio_tx_source(const uint16_t *adc_slice, uint32_t n)
{
    /* Sized for BLOCK_SIZE_ANALOG, not BLOCK_SIZE_MAX: only the
       non-buffered (analog) TX path calls this, where n is always
       block_size/2 = 256. The buffered FreeDV path has its own tx_mic
       buffer and never gets here. Sizing these for BLOCK_SIZE_MAX pushed
       .bss past the point where FreeDV's heap allocation starts failing
       (see the ring-size history in usbd_audio_duplex.h). */
    static uint16_t usb_tx_buf[BLOCK_SIZE_ANALOG / 2];
    static int16_t  pcm[BLOCK_SIZE_ANALOG / 2];

    if (audio_source != AUDIO_SRC_USB || n > (BLOCK_SIZE_ANALOG / 2))
        return adc_slice;

    if (usb_tx_testtone)
    {
        /* Phase kept across blocks so the sine is continuous - a phase
           reset every block would itself be an audible discontinuity and
           would invalidate the test. */
        static float ph = 0.0f;
        const float dph = 2.0f * (float)M_PI * 1000.0f / 48000.0f;

        for (uint32_t i = 0; i < n; i++)
        {
            pcm[i] = (int16_t)(sinf(ph) * 20000.0f);
            ph += dph;
            if (ph > TWO_PI) ph -= TWO_PI;
        }
    }
    else
    {
        USBD_AUDIO_DUPLEX_GetSpeakerAudio(&hUsbDeviceFS, pcm, n);
    }

    /* Every mode's TX function multiplies its input by mic_gain (1..200),
       calibrated to boost a real microphone's typically weak analog swing
       up to a usable modulation level. USB PCM audio is already at full
       digital scale, so applying that same gain a second time massively
       over-deviates the modulator. Dividing by mic_gain alone isn't
       enough, though: at mic_gain=1 (its default, and what it's set to
       right now) that division is a no-op, and confirmed on hardware via
       telemetry - rx_adc_peak pinned at exactly 1.0, i.e. hard-clipping
       the ADC representation, on every single block - a full-scale
       digital PCM source has zero headroom once mapped 1:1 onto the ADC's
       swing. That clipping's sharp edges is what was misread as "chopped"
       on a waterfall: it's splattered FM deviation from a clipped
       modulating signal, not a dropout (usb_spk_under was confirmed 0 the
       entire time this was measured). USB_HEADROOM builds in real margin
       independent of mic_gain, since PC-sourced digital audio routinely
       sits near 0 dBFS in a way a real mic's raw signal never does;
       mic_gain still works as an additional multiplier on top for
       whoever wants it louder, up to where it clips again. */
    const float USB_HEADROOM = 0.5f;   /* -6 dB before mic_gain is applied */
    float inv_gain = USB_HEADROOM / mic_gain;
    for (uint32_t i = 0; i < n; i++)
    {
        int32_t scaled = (int32_t)((float)pcm[i] * inv_gain);
        if (scaled >  32767) scaled =  32767;
        if (scaled < -32768) scaled = -32768;
        usb_tx_buf[i] = pcm16_to_sample((int16_t)scaled);
    }

    return usb_tx_buf;
}

/* Call right after an RX process_block() writes its DAC slice: when
   SRC_USB, send that audio to the PC as "microphone" input instead of
   (not in addition to) DAC1 - mirroring it out both places would leave
   the physical speaker always live regardless of the src setting, which
   is exactly the "switching src does nothing audible" bug this fixes.
   usb_audio_tx_inject() already replaces rather than mirrors on the TX
   side; this makes RX symmetric with it. */
volatile float    usb_mic_peak  = 0.0f;  /* peak |pcm|/32768 fed to the USB mic ring, since last report */
volatile uint32_t usb_mic_calls = 0;     /* how many times this ran, since last report */

/* Shared staging buffer for both functions below. They are mutually
   exclusive in time - this one only runs from the RX branch (!tx_active),
   usb_audio_mic_tx_update() only runs during tx_active - so one static
   array safely serves both instead of two, since every static byte here
   competes with FreeDV's OFDM/LDPC heap (bss growth has hung FreeDV
   mode-switching before, confirmed on hardware). Sized for the largest
   caller on either side: RX's and FreeDV TX's buffered-mode blocks can
   both run up to BLOCK_SIZE_MAX/2 samples. */
static int16_t usb_mic_pcm[BLOCK_SIZE_MAX / 2];

static void usb_audio_rx_capture(uint16_t *dac_slice, uint32_t n)
{
    if (audio_source != AUDIO_SRC_USB)
    {
        /* USB isn't the active listening path - mute it explicitly rather
           than leave stale content in the ring for the IN endpoint ISR to
           keep replaying to whatever's listening over USB. dac_slice is
           deliberately left untouched: the analog jack still needs the
           real demodulated audio process_block() already wrote there. */
        for (uint32_t i = 0; i < n; i++)
            usb_mic_pcm[i] = 0;
        USBD_AUDIO_DUPLEX_FeedMic(&hUsbDeviceFS, usb_mic_pcm, n);
        return;
    }

    usb_mic_calls++;

    for (uint32_t i = 0; i < n; i++)
    {
        usb_mic_pcm[i] = sample_to_pcm16(dac_slice[i]);
        dac_slice[i] = DAC_MID;
        /* Peak tracking (usb_mic_peak) temporarily disabled, 2026-08-06:
           isolating whether this per-sample float math - the one thing
           that runs on the USB branch and not on analog's plain
           zero-fill branch - is connected to a regularly-spaced
           small-amplitude-spike report. Re-enable once that's answered
           either way. */
#if 0
        float mag = (usb_mic_pcm[i] < 0 ? -(float)usb_mic_pcm[i] : (float)usb_mic_pcm[i]) / 32768.0f;
        if (mag > usb_mic_peak) usb_mic_peak = mag;
#endif
    }
    USBD_AUDIO_DUPLEX_FeedMic(&hUsbDeviceFS, usb_mic_pcm, n);
}

/* USB mic (IN) direction during TX. CW's sidetone is the only thing with
   legitimate content to send over USB - mirrors the analog DAC1/headphone
   jack, which also only carries live audio during CW TX (see
   audio_dma_start()). Every other case (any non-CW mode, or CW while
   audio_source is still analog) explicitly mutes USB instead of leaving
   it fed by whatever was last written before TX started, same principle
   as the DAC1 mute fix in audio_dma_start() applied to the USB direction.
   side_slice may be NULL when the caller has no monitor buffer at all
   (FreeDV TX) - safe, since it's only read in the MODE_CW branch, which
   FreeDV can never take. Called once per TX block from the call sites
   below rather than from inside tx_process_block() itself, so CW's real
   content and every other mode's silence each go through exactly one
   FeedMic() call, never both. */
static void usb_audio_mic_tx_update(uint16_t *side_slice, uint32_t n)
{
    if (MODE == MODE_CW && audio_source == AUDIO_SRC_USB)
    {
        for (uint32_t i = 0; i < n; i++)
        {
            usb_mic_pcm[i] = sample_to_pcm16(side_slice[i]);
            side_slice[i] = DAC_MID;
        }
    }
    else
    {
        for (uint32_t i = 0; i < n; i++)
            usb_mic_pcm[i] = 0;
    }
    USBD_AUDIO_DUPLEX_FeedMic(&hUsbDeviceFS, usb_mic_pcm, n);
}

/* hmi.c toggles audio routing via BTN_ENTER without needing to know the
   audio_src_t type - same arm's-length pattern it already uses for mode/
   PTT/CW pitch via radio_set_mode()/radio_tx_on()/cw_set_pitch(). */
int audio_source_is_usb(void) { return audio_source == AUDIO_SRC_USB; }

int mode_is_freedv(int mode);   /* defined further down; needed here too */

/* Single place audio_source ever changes - the console `src` command used
   to set it directly too, bypassing this. Nothing drains the USB speaker
   (OUT) ring while it isn't the active TX source (during RX regardless of
   audio_source, or during TX while audio_source is analog), so it can
   accumulate a real backlog - same staleness problem radio_tx_on() already
   resets for on every TX start, just reachable from a second trigger: a
   mid-session source switch, including mid-TX. Resetting unconditionally
   rather than only when switching *to* USB is deliberate - trivially cheap
   when the ring was already idle (see USBD_AUDIO_DUPLEX_ResetSpeaker()),
   and avoids having to reason about which direction actually needs it. */
static void audio_source_set(audio_src_t src)
{
    if (src == audio_source)
        return;

    /* FreeDV decode is main-loop CPU, mode-gated, not audio_source-gated -
       it runs whenever MODE is a FreeDV mode, regardless of where the
       result goes. On this MCU it already sits at ~125% of real-time
       budget doing that decode alone (confirmed on hardware 2026-08-06,
       700D: ~42-53ms per 40ms block) - tolerable in isolation (backlog
       stays bounded, audio comes out understandable), but USB audio's own
       ~1 kHz ISR servicing adds enough on top to push it past whatever
       point the ring backlog and codec2's per-packet malloc/free churn
       stop being recoverable: confirmed hard fault inside newlib's
       allocator, then persistent codec2_calloc() failures once triggered.
       Decided answer, not a workaround: FreeDV is analog-only (still
       fully standalone, no PC needed there) and audio:usb is scoped to
       ssb/cw/am/fm, which never showed this problem. See
       radio_apply_mode() for the other half - switching *into* a FreeDV
       mode while already on usb. */
    if (src == AUDIO_SRC_USB && mode_is_freedv(MODE))
    {
        uart_puts("FreeDV is analog-only - switch mode first\r\n");
        return;
    }

    audio_source = src;
    USBD_AUDIO_DUPLEX_ResetSpeaker(&hUsbDeviceFS);
    USBD_AUDIO_DUPLEX_ResetMic(&hUsbDeviceFS);
    /* radio_apply_mode() and radio_tx_on()/radio_tx_off() all flush filter/
       NCO/CW-BPF history via dsp_filters_init() before restarting DMA - a
       plain source switch never did, so switching usb->analog->usb (no mode
       or PTT in between) kept whatever filter state was running from before.
       Confirmed 2026-08-06 the hum this was chasing is heard over usb only
       (not analog) and alternates - present, then gone, then back again on
       the switch after that - so this alone isn't the full story, but it's
       still a real gap other switch paths already close, so keeping it. */
    dsp_filters_init();
    /* Needed now so the DAC1-DMA-vs-parked choice in audio_dma_start()'s
       RX branch actually takes effect on a source switch, not just on the
       next mode change or PTT - those already call this, a plain source
       switch never did before. */
    audio_dma_restart();

    /* Diagnostic, 2026-08-06: precise per-switch snapshot to pin down the
       alternating usb-only hum above - cumulative counters (not reset here,
       only the periodic report owns that) so consecutive switches can be
       told apart by their deltas even faster than the ~1 s report cadence. */
    {
        extern volatile uint32_t usb_mic_underruns, usb_mic_fade_ins, usb_mic_fade_outs;
        static uint32_t switch_n = 0;
        switch_n++;
        uart_kv("src_switch_n", (int)switch_n);
        uart_kv("src_switch_to", (int)src);   /* AUDIO_SRC_USB/ANALOG - see enum */
        uart_kv("mic_under_at_sw", (int)usb_mic_underruns);
        uart_kv("mic_fadein_at_sw", (int)usb_mic_fade_ins);
        uart_kv("mic_fadeout_at_sw", (int)usb_mic_fade_outs);
        uart_puts("\r\n");
    }
}

void audio_source_toggle(void)
{
    audio_source_set(audio_source == AUDIO_SRC_USB ? AUDIO_SRC_ANALOG : AUDIO_SRC_USB);
}

static void audio_dma_restart(void)
{
    HAL_ADC_Stop_DMA(&hadc1);
    HAL_ADC_Stop_DMA(&hadc2);
    HAL_DAC_Stop_DMA(&hdac, DAC_CHANNEL_1);
    HAL_DAC_Stop_DMA(&hdac, DAC_CHANNEL_2);
    audio_dma_start();
}

/*
 * Half duplex: exactly one ADC and DAC_OUT2/DAC_OUT1 pair carries the
 * "live" signal at a time, chosen by tx_active. RX reads IF off hadc1 (PC0)
 * and writes demodulated audio to DAC_OUT1 (PA4). TX reads the mic off
 * hadc2 (PA3) and writes modulated IF to DAC_OUT2 (PA5). adc_buffer/
 * dac_buffer stay the generic "current input/output" pair either way -- the
 * DSP code does not need to know which side is live.
 *
 * One exception: DAC_OUT1 also keeps running during CW TX, carrying the
 * sidetone (see cw_tx_process_block()) so keying is heard through the
 * speaker/phones the same as [[cw-design-decisions]] always intended.
 */
static void audio_dma_start(void)
{
    for (uint32_t i = 0; i < DAC_RING_LEN; i++)
        dac_buffer[i] = DAC_MID;

    for (uint32_t i = 0; i < BLOCK_SIZE_ANALOG; i++)
        sidetone_buffer[i] = DAC_MID;

    memset(adc_buffer, 0, sizeof(adc_buffer));

    block_ready          = 0;
    dac_block_processing = 0;

    adc_rd = 0;

    uint32_t dac_len = (tx_active && mode_is_buffered(MODE)) ? DAC_RING_LEN
                                                             : block_size;
    uint32_t adc_len = mode_is_buffered(MODE) ? ADC_RING_LEN : block_size;

    if (tx_active)
    {
        HAL_DAC_Start_DMA(&hdac, DAC_CHANNEL_2, (uint32_t *)dac_buffer, dac_len, DAC_ALIGN_12B_R);
        if (MODE == MODE_CW)
            HAL_DAC_Start_DMA(&hdac, DAC_CHANNEL_1, (uint32_t *)sidetone_buffer, dac_len, DAC_ALIGN_12B_R);
        else
        {
            /* Every other mode leaves DAC_OUT1 (headphone/speaker) with no
               signal of its own on TX. HAL_DAC_Stop_DMA() above disabled
               the channel outright, so the pin was floating into the LM386
               stage - audible as a drone/hum picked up from TX-side
               switching noise. Park it at a defined silent level instead
               of leaving it undriven. */
            HAL_DAC_Start(&hdac, DAC_CHANNEL_1);
            HAL_DAC_SetValue(&hdac, DAC_CHANNEL_1, DAC_ALIGN_12B_R, DAC_MID);
        }
        HAL_ADC_Start_DMA(&hadc2, (uint32_t *)adc_buffer, adc_len);
    }
    else
    {
        /* Experiment, 2026-08-06: audio_source == USB used to still run
           DAC1's DMA continuously, playing whatever usb_audio_rx_capture()
           had just silenced dac_buffer to - same content either way (the
           headphone jack is silent regardless), but DAC1's own DMA
           completion interrupts kept firing at a steady, regular rate the
           whole time, chasing a report of small, *regularly-spaced*
           amplitude spikes specifically over audio:usb. Parking DAC1 at a
           static value instead of DMA-ing it removes that interrupt
           activity entirely rather than just muting its content - same
           pattern as the TX-mute fix above, applied here to test whether
           DAC1's DMA cadence was ever interacting with the USB audio
           pipeline's timing. Zero effect on what's actually heard either
           way, since the analog jack is silent under audio:usb regardless
           of which of these two runs. */
        if (audio_source == AUDIO_SRC_USB)
        {
            HAL_DAC_Start(&hdac, DAC_CHANNEL_1);
            HAL_DAC_SetValue(&hdac, DAC_CHANNEL_1, DAC_ALIGN_12B_R, DAC_MID);
        }
        else
        {
            HAL_DAC_Start_DMA(&hdac, DAC_CHANNEL_1, (uint32_t *)dac_buffer, dac_len, DAC_ALIGN_12B_R);
        }
        HAL_ADC_Start_DMA(&hadc1, (uint32_t *)adc_buffer, adc_len);
    }
}

/*
 * Switch demodulator, and with it the block size.
 *
 * FreeDV wants 40 ms blocks so each one is exactly a modem frame; the analog
 * modes want short ones so CW break-in is not buried under latency. The DMA
 * length is fixed when it is started, so changing it means stopping and
 * restarting both streams.
 */
/*
 * Everything that varies per mode, in one table.
 *
 * Keeping it here rather than scattered through if-chains means a front panel
 * menu only has to index this array, and adding a mode is one row rather than
 * edits in five places.
 *
 * buffered: run the DSP out of a ring buffer instead of straight off the DMA
 * half-buffer. Buffered decouples processing time from the block period, which
 * the FreeDV modes need; direct keeps latency at one block, which is what CW
 * break-in wants. See the audio input ring below.
 */
typedef struct {
    const char *name;
    uint32_t    block_size;
    uint8_t     buffered;
    int8_t      chain_mode;   /* FREEDV_CHAIN_MODE_*, or -1 if not FreeDV */
} mode_cfg_t;

static const mode_cfg_t mode_cfg[] = {
    [MODE_NBFM]         = { "NBFM",  BLOCK_SIZE_ANALOG, 0, -1 },
    [MODE_USB]          = { "USB",   BLOCK_SIZE_ANALOG, 0, -1 },
    [MODE_LSB]          = { "LSB",   BLOCK_SIZE_ANALOG, 0, -1 },
    [MODE_FREEDV]       = { "FreeDV 1600",  BLOCK_SIZE_FREEDV, 1, FREEDV_CHAIN_MODE_1600  },
    [MODE_FREEDV_2400B] = { "FreeDV 2400B", BLOCK_SIZE_2400B,  1, FREEDV_CHAIN_MODE_2400B },
    [MODE_FREEDV_700D]  = { "FreeDV 700D",  BLOCK_SIZE_700D,   1, FREEDV_CHAIN_MODE_700D  },
    [MODE_FREEDV_700E]  = { "FreeDV 700E",  BLOCK_SIZE_700E,   1, FREEDV_CHAIN_MODE_700E  },
    [MODE_AM]           = { "AM",    BLOCK_SIZE_ANALOG, 0, -1 },
    [MODE_CW]           = { "CW",    BLOCK_SIZE_ANALOG, 0, -1 },
};

#define MODE_COUNT ((int)(sizeof(mode_cfg) / sizeof(mode_cfg[0])))

static const mode_cfg_t *cfg_for(int mode)
{
    if (mode < 0 || mode >= MODE_COUNT || mode_cfg[mode].name == NULL)
        return &mode_cfg[MODE_USB];
    return &mode_cfg[mode];
}

uint32_t block_size_for(int mode) { return cfg_for(mode)->block_size; }
int      mode_is_freedv(int mode) { return cfg_for(mode)->chain_mode >= 0; }
int      chain_mode_for(int mode) { return cfg_for(mode)->chain_mode; }
int      mode_is_buffered(int mode) { return cfg_for(mode)->buffered; }
const char *mode_name(int mode)   { return cfg_for(mode)->name; }
int      mode_count(void)         { return MODE_COUNT; }

/*
 * Largest block malloc() can still hand out. codec2 allocates its modem state
 * in a few big chunks (2400A's f_dc alone is about 65K), so this is a better
 * predictor of whether freedv_open() will succeed than total free bytes.
 */
static uint32_t heap_largest_free(void)
{
    uint32_t lo = 0, hi = 256u * 1024u;

    while (lo < hi)
    {
        uint32_t mid = (lo + hi + 1u) / 2u;
        void    *p   = malloc(mid);

        if (p) { free(p); lo = mid; }
        else   { hi = mid - 1u; }
    }
    return lo;
}

/*
 * Does the actual work of switching to `mode`: stop DMA, apply the new
 * mode/block_size, resync the USB mic ring, reflush filter state, open or
 * reset the FreeDV chain, restart DMA. Split out from radio_set_mode() so
 * main() can run this exact same sequence once at boot - unconditionally,
 * bypassing radio_set_mode()'s no-op guard below - instead of hand-picking
 * a subset of it. A partial boot-time replica (just dsp_filters_init() +
 * audio_dma_start(), then a second attempt adding ResetSpeaker()/ResetMic()
 * on top, both tried 2026-08-06) left small, regularly-spaced amplitude
 * spikes heard only over audio:usb unaffected, even though a live mode or
 * source switch fixes them permanently - so whatever actually fixes it
 * needs the *whole* sequence a live switch runs, not a hand-picked part of
 * it, hence running the real thing at boot instead of guessing again.
 */
static void radio_apply_mode(int mode)
{
    /* FreeDV is analog-only (see audio_source_set()'s guard for why) - this
       is the other half, switching *into* a FreeDV mode while already on
       audio:usb. Auto-switch rather than refuse: audio_source_set() alone
       can reject a usb request made *while* already in a FreeDV mode, but
       a mode change has nowhere sensible to "refuse" to - the mode change
       itself is what the user asked for - so drop back to analog instead
       of leaving them on a source that's about to go silent for this mode.
       Runs before this function's own DMA stop/start below, as a
       self-contained switch, rather than interleaving with it. */
    if (mode_is_freedv(mode) && audio_source == AUDIO_SRC_USB)
    {
        audio_source_set(AUDIO_SRC_ANALOG);
    }

    uint32_t want = block_size_for(mode);

    HAL_ADC_Stop_DMA(&hadc1);
    HAL_ADC_Stop_DMA(&hadc2);
    HAL_DAC_Stop_DMA(&hdac, DAC_CHANNEL_1);
    HAL_DAC_Stop_DMA(&hdac, DAC_CHANNEL_2);

    MODE       = mode;
    block_size = want;

    // Every mode can have a different block size/cadence, which can leave
    // the USB mic ring's read/write pointers in a relationship the IN
    // endpoint ISR's pacing never recovers from on its own - heard as
    // continuous crackle until src is toggled away and back. Cheap and
    // harmless to call unconditionally, same as ResetSpeaker() already is.
    USBD_AUDIO_DUPLEX_ResetMic(&hUsbDeviceFS);

    // Filter history and the FreeDV resamplers hold audio from the old mode at
    // the old block size, so flush both rather than let it bleed through.
    dsp_filters_init();

    if (mode_is_freedv(mode))
    {
        // 1600 and 2400A are different modems, so this reopens codec2 rather
        // than just flushing what is buffered. Bracketed with heap probes so
        // a hang can be placed as "inside freedv_chain_init()'s allocation"
        // (only the _before line shows up) vs. "after a clean open, once
        // real decoding starts" (both lines show up, then it hangs later).
        uart_kv("heap_before_open", (int)heap_largest_free());
        uart_puts("\r\n");

        freedv_ok = (freedv_chain_init(chain_mode_for(mode)) == 0);

        uart_puts(freedv_ok ? "freedv: ready\r\n"
                            : "freedv: init FAILED\r\n");
        uart_kv("heap_after_open", (int)heap_largest_free());
        uart_puts("\r\n");
    }
    else if (freedv_ok)
    {
        freedv_chain_reset();
    }

    audio_dma_start();
}

void radio_set_mode(int mode)
{
    uint32_t want = block_size_for(mode);

    if (mode == MODE && want == block_size)
        return;

    radio_apply_mode(mode);
}

/*
 * FreeDV 2400A receive.
 *
 * 2400A rides inside an ordinary FM channel, so this is the FM path, not the
 * SSB one: mix the 12 kHz IF down, filter the channel wide enough to keep the
 * 4FSK tones intact, and FM demodulate. What comes out is the modem's own
 * 48 kHz signal, which goes straight to the demodulator without resampling.
 *
 * Deliberately no post-demod audio LPF: the voice filter would cut the 4800 Hz
 * tone and the modem would never sync.
 */
void freedv2400b_process_block(const uint16_t *in, uint16_t *out, int n)
{
    float *I_buf     = &dsp_scratch[0 * SCRATCH_N];
    float *Q_buf     = &dsp_scratch[1 * SCRATCH_N];
    float *audio_buf = &dsp_scratch[2 * SCRATCH_N];

    float *IQ_in     = &dsp_scratch[3 * SCRATCH_N];
    float *NCO_buf   = &dsp_scratch[5 * SCRATCH_N];
    float *IQ_mix    = &dsp_scratch[7 * SCRATCH_N];
    float *nbfm_raw  = &dsp_scratch[9 * SCRATCH_N];   // FreeDV fallback audio, see below

    float adc_peak = 0.0f;

    for (int i = 0; i < n; i++)
    {
        uint32_t raw = in[i] & 0x0FFF;
        I_buf[i] = ((float)raw - 2048.0f) / 2048.0f;

        float a = fabsf(I_buf[i]);
        if (a > adc_peak) adc_peak = a;
    }
    rx_adc_peak = adc_peak;

    arm_fir_f32(&hilbert, I_buf, Q_buf, n);

    for (int i = 0; i < n; i++)
    {
        IQ_in[2*i + 0] = I_buf[i];
        IQ_in[2*i + 1] = Q_buf[i];
    }

    nco_block_iq(NCO_buf, n);
    arm_cmplx_mult_cmplx_f32(IQ_in, NCO_buf, IQ_mix, n);

    for (int i = 0; i < n; i++)
    {
        I_buf[i] = IQ_mix[2*i + 0];
        Q_buf[i] = IQ_mix[2*i + 1];
    }

    // The ordinary voice channel filter is right here: 2400B is specified to
    // survive a 300-3000 Hz audio path, so it fits inside NBFM as it stands.
    arm_fir_f32(&pre_fm_I, I_buf, I_buf, n);
    arm_fir_f32(&pre_fm_Q, Q_buf, Q_buf, n);

    // Data discriminator, not the voice one: no de-emphasis, no voice AGC.
    fm_discriminate(I_buf, Q_buf, audio_buf, n);

    /*
     * Peak alone cannot tell an over-deviated signal from an occasional noise
     * spike, so track rms as well. A clean FM data signal sits around peak/rms
     * of 3-4; a much larger ratio means the discriminator is spiking, and a
     * peak near 1.0 with high rms means the deviation itself is too big and
     * atan2 is wrapping.
     */
    float peak = 0.0f;
    float sumsq = 0.0f;

    for (int i = 0; i < n; i++)
    {
        float a = fabsf(audio_buf[i]);
        if (a > peak) peak = a;
        sumsq += audio_buf[i] * audio_buf[i];
    }

    rx_peak = peak;
    rx_rms  = sqrtf(sumsq / (float)n);
    rx_blocks++;

    // Listen on plain NBFM until 2400B syncs, same idea (and same reason)
    // as the SSB-mode fallback in ssb_process_block(): audio_buf is about
    // to be overwritten with decoded speech or decoder noise, so save the
    // discriminator output first and fall back to it if not synced.
    memcpy(nbfm_raw, audio_buf, n * sizeof(float));

    if (freedv_ok)
    {
        uint32_t t0 = DWT->CYCCNT;

        freedv_chain_put_audio48(audio_buf, n);
        freedv_chain_get_speech48(audio_buf, n);

        uint32_t dt = DWT->CYCCNT - t0;
        if (dt > rx_fdv_cycles_max)
            rx_fdv_cycles_max = dt;
    }

    if (!freedv_ok || !freedv_chain_synced())
        memcpy(audio_buf, nbfm_raw, n * sizeof(float));

    for (int i = 0; i < n; i++)
    {
        float y = audio_buf[i] * 1500.0f + 2048.0f;

        if (y < 0.0f)    y = 0.0f;
        if (y > 4095.0f) y = 4095.0f;

        out[i] = (uint16_t)y;
    }
}

/*
 * AM receive.
 *
 * Deliberately not routed through the SSB path. That one builds its complex
 * signal with a Hilbert transformer, which AM does not need: mixing the real
 * IF against cos and -sin gives I and Q directly, and the existing channel
 * filter removes the sum-frequency image. Skipping the Hilbert removes both
 * its quadrature error and its group delay, neither of which the envelope
 * detector can tolerate -- any I/Q imbalance turns straight into amplitude
 * error, and the whole point of AM is that the amplitude is the signal.
 *
 * The envelope is then |I + jQ|, which needs no knowledge of the carrier
 * phase and, unlike SSB, is completely unaffected by a tuning offset.
 */
void am_process_block(const uint16_t *in, uint16_t *out, int n)
{
    float *I_buf     = &dsp_scratch[0 * SCRATCH_N];
    float *Q_buf     = &dsp_scratch[1 * SCRATCH_N];
    float *audio_buf = &dsp_scratch[2 * SCRATCH_N];
    float *NCO_buf   = &dsp_scratch[3 * SCRATCH_N];   /* interleaved, 2n */

    static dc_block_t dc_am  = {0};
    static agc_t      agc_am = {1.0f};

    float adc_peak = 0.0f;

    nco_block_iq(NCO_buf, n);

    for (int i = 0; i < n; i++)
    {
        float x = ((float)(in[i] & 0x0FFF) - 2048.0f) / 2048.0f;

        float a = fabsf(x);
        if (a > adc_peak) adc_peak = a;

        /* Quadrature downconversion: multiply by exp(-j*w*t). */
        I_buf[i] =  x * NCO_buf[2*i + 0];
        Q_buf[i] = -x * NCO_buf[2*i + 1];
    }

    rx_adc_peak = adc_peak;

    /* Removes the image at twice the IF that the mixing leaves behind. */
    arm_fir_f32(&pre_fm_I, I_buf, I_buf, n);
    arm_fir_f32(&pre_fm_Q, Q_buf, Q_buf, n);

    float peak = 0.0f, sumsq = 0.0f;
    float env_min = 1e9f, env_sum = 0.0f;

    for (int i = 0; i < n; i++)
    {
        float env = sqrtf(I_buf[i] * I_buf[i] + Q_buf[i] * Q_buf[i]);

        /*
         * env_min against env_avg says whether the transmitter sent a carrier.
         * Proper AM never lets the envelope reach zero, so env_min stays near
         * (1 - m) of the mean. If env_min collapses to zero the envelope is
         * being rectified, which is what a suppressed carrier looks like and
         * why the tone comes out at twice its frequency.
         */
        if (env < env_min) env_min = env;
        env_sum += env;

        /* The carrier is a DC pedestal under the envelope; drop it. */
        audio_buf[i] = dc_block(env, &dc_am);

        float a = fabsf(audio_buf[i]);
        if (a > peak) peak = a;
        sumsq += audio_buf[i] * audio_buf[i];
    }

    rx_env_min = env_min;
    rx_env_avg = env_sum / (float)n;
    rx_peak = peak;
    rx_rms  = sqrtf(sumsq / (float)n);
    rx_blocks++;

    agc_block(audio_buf, n, &agc_am);

    for (int i = 0; i < n; i++)
    {
        float y = audio_buf[i] * 1500.0f + 2048.0f;

        if (y < 0.0f)    y = 0.0f;
        if (y > 4095.0f) y = 4095.0f;

        out[i] = (uint16_t)y;
    }
}

/* ------------------------------------------------------------------------
 * SSB transmit, phasing method
 *
 * Audio is band limited, split into a quadrature pair, and mixed up to the IF:
 *
 *   USB:  I*cos(wt) - Q*sin(wt)
 *   LSB:  I*cos(wt) + Q*sin(wt)
 *
 * where Q is the Hilbert transform of the audio and I is the audio delayed by
 * the transformer's group delay, so the two stay aligned.
 *
 * The Hilbert is 301 taps, which looks excessive until you notice that 300 Hz
 * is 0.6 % of Nyquist at 48 kHz, and a Hilbert transformer is at its worst
 * near DC. Fewer taps cost real opposite-sideband suppression: 129 taps manage
 * only about 18 dB, 201 give 30 dB, 301 give 56 dB. Transmitting the unwanted
 * sideband is other people's problem as much as ours, so it is worth the
 * arithmetic -- and transmit does not run at the same time as receive, so the
 * whole CPU budget is free anyway.
 * --------------------------------------------------------------------- */

#define SSB_HIL_TAPS  301
#define SSB_HIL_DELAY ((SSB_HIL_TAPS - 1) / 2)

static float ssb_hil_coeffs[SSB_HIL_TAPS];
/*
 * State is sized for the analog block, so anything longer must be fed through
 * in pieces: CMSIS writes numTaps + blockSize - 1 floats here, and the FreeDV
 * path calls this with 1920 where the analog modes use 256.
 */
#define SSB_HIL_MAXBLK (BLOCK_SIZE_ANALOG / 2)

static float ssb_hil_state[SSB_HIL_TAPS + SSB_HIL_MAXBLK];
static arm_fir_instance_f32 ssb_hil;

/* Speech band limiting: high pass at 300 Hz, low pass at 2700 Hz. */
static const float ssb_audio_coeffs[10] = {
    +9.7260993065e-01f,
    -1.9452198613e+00f,
    +9.7260993065e-01f,
    +1.9444697251e+00f,
    -9.4596999747e-01f,
    +2.4827170061e-02f,
    +4.9654340121e-02f,
    +2.4827170061e-02f,
    +1.5074026397e+00f,
    -6.0671131993e-01f
};
static float ssb_audio_state[8];
static arm_biquad_casd_df1_inst_f32 ssb_audio;

/* Delay line for the I branch, matching the Hilbert group delay. */
static float ssb_delay[SSB_HIL_DELAY];
static int   ssb_delay_pos;

/*
 * Microphone gain. A dynamic mic into a 3.3 V ADC input needs a lot of it, and
 * without any the modulator is fed a signal that barely leaves the noise
 * floor. Adjustable from the console so the level can be set while watching
 * adc_x1000 and the scope.
 */
float mic_gain = 1.0f;

static float ssb_osc_re = 1.0f, ssb_osc_im = 0.0f;
static float ssb_step_re, ssb_step_im;

static void ssb_tx_init(void)
{
    const int M = SSB_HIL_DELAY;

    for (int i = 0; i < SSB_HIL_TAPS; i++)
    {
        int n = i - M;

        if (n == 0 || (n % 2) == 0)
        {
            ssb_hil_coeffs[i] = 0.0f;   /* a Hilbert has no even-index taps */
            continue;
        }

        float w = 0.54f - 0.46f * cosf(2.0f * (float)M_PI * (float)i
                                       / (float)(SSB_HIL_TAPS - 1));

        ssb_hil_coeffs[i] = 2.0f / ((float)M_PI * (float)n) * w;
    }

    arm_fir_init_f32(&ssb_hil, SSB_HIL_TAPS, ssb_hil_coeffs,
                     ssb_hil_state, SSB_HIL_MAXBLK);
    arm_biquad_cascade_df1_init_f32(&ssb_audio, 2,
                                    (float *)ssb_audio_coeffs, ssb_audio_state);
}

void ssb_tx_restart(void)
{
    float dphi = 2.0f * (float)M_PI * 12000.0f / 48000.0f;

    ssb_step_re = cosf(dphi);
    ssb_step_im = sinf(dphi);
    ssb_osc_re  = 1.0f;
    ssb_osc_im  = 0.0f;

    for (int i = 0; i < SSB_HIL_DELAY; i++) ssb_delay[i] = 0.0f;
    ssb_delay_pos = 0;
}

/*
 * Run the Hilbert in chunks no larger than the state was sized for. The filter
 * keeps its own history between calls, so splitting the block changes nothing
 * about the output -- it only keeps CMSIS from writing past the state buffer.
 */
static void ssb_hilbert(const float *in, float *out, int n)
{
    for (int off = 0; off < n; off += SSB_HIL_MAXBLK)
    {
        int m = n - off;

        if (m > SSB_HIL_MAXBLK) m = SSB_HIL_MAXBLK;

        arm_fir_f32(&ssb_hil, (float *)&in[off], &out[off], m);
    }
}

/*
 * Modulate a ready audio buffer. Split out so the FreeDV path can reach it:
 * a modem waveform must not be run through the speech band pass or the
 * microphone gain, since it is already shaped and any further filtering or
 * compression distorts it.
 */
static void ssb_modulate(const float *audio, const float *q,
                         uint16_t *out, int n, int lsb)
{
    for (int i = 0; i < n; i++)
    {
        float d = ssb_delay[ssb_delay_pos];

        ssb_delay[ssb_delay_pos] = audio[i];
        if (++ssb_delay_pos >= SSB_HIL_DELAY) ssb_delay_pos = 0;

        float s = lsb ? (d * ssb_osc_re + q[i] * ssb_osc_im)
                      : (d * ssb_osc_re - q[i] * ssb_osc_im);

        float nre = ssb_osc_re * ssb_step_re - ssb_osc_im * ssb_step_im;
        float nim = ssb_osc_re * ssb_step_im + ssb_osc_im * ssb_step_re;
        float g   = 1.5f - 0.5f * (nre * nre + nim * nim);

        ssb_osc_re = nre * g;
        ssb_osc_im = nim * g;

        float y = s * 1800.0f + 2048.0f;

        if (y < 0.0f)    y = 0.0f;
        if (y > 4095.0f) y = 4095.0f;

        out[i] = (uint16_t)y;
    }
}

void ssb_tx_process_block(const uint16_t *in, uint16_t *out, int n)
{
    float *audio = &dsp_scratch[0 * SCRATCH_N];
    float *q     = &dsp_scratch[1 * SCRATCH_N];

    float peak = 0.0f;

    for (int i = 0; i < n; i++)
    {
        float x = ((float)(in[i] & 0x0FFF) - 2048.0f) / 2048.0f;

        float a = fabsf(x);
        if (a > peak) peak = a;

        audio[i] = x * mic_gain;
    }

    rx_adc_peak = peak;                 /* raw mic level, before the gain */
    rx_blocks++;

    arm_biquad_cascade_df1_f32(&ssb_audio, audio, audio, n);
    ssb_hilbert(audio, q, n);

    /* USB/LSB swapped vs the phasing convention so the label matches the air,
       confirmed against an FT-857D. FreeDV keeps the plain USB call below. */
    ssb_modulate(audio, q, out, n, MODE == MODE_USB);
}

/* ------------------------------------------------------------------------
 * CW transmit
 *
 * Sends a beacon at the IF the receiver is tuned to. The carrier sits at
 * cw_pitch_hz above the IF centre, which is the same offset the receive
 * filter is centred on: a station whose carrier gives us a 700 Hz tone is on
 * the frequency we have to answer on, so transmit has to land in the same
 * place.
 *
 * The envelope is shaped rather than switched. Hard keying splatters well
 * outside the occupied bandwidth -- key clicks are one of the more common
 * complaints on the CW bands -- so each edge is a raised cosine a few
 * milliseconds long.
 * --------------------------------------------------------------------- */

#define CW_MSG_DEFAULT "LA7LKA DE LB2S LB2S LB2S"
#define CW_MSG_MAXLEN  40                   /* text chars; cw_build_message()
                                                already bounds-checks against
                                                CW_UNITS below, so an
                                                over-length message just gets
                                                truncated safely, not overrun */
#define CW_UNITS    256                     /* dit units in the keyed message */
#define CW_RAMP     240                     /* 5 ms edge at 48 kHz */

static const char *cw_morse(char c)
{
    switch (c) {
    case 'A': return ".-";    case 'B': return "-...";  case 'C': return "-.-.";
    case 'D': return "-..";   case 'E': return ".";     case 'F': return "..-.";
    case 'G': return "--.";   case 'H': return "....";  case 'I': return "..";
    case 'J': return ".---";  case 'K': return "-.-";   case 'L': return ".-..";
    case 'M': return "--";    case 'N': return "-.";    case 'O': return "---";
    case 'P': return ".--.";  case 'Q': return "--.-";  case 'R': return ".-.";
    case 'S': return "...";   case 'T': return "-";     case 'U': return "..-";
    case 'V': return "...-";  case 'W': return ".--";   case 'X': return "-..-";
    case 'Y': return "-.--";  case 'Z': return "--..";
    case '0': return "-----"; case '1': return ".----"; case '2': return "..---";
    case '3': return "...--"; case '4': return "....-"; case '5': return ".....";
    case '6': return "-...."; case '7': return "--..."; case '8': return "---..";
    case '9': return "----.";
    default:  return "";
    }
}

static uint8_t cw_key[CW_UNITS];    /* one entry per dit unit, 1 = key down */
static int     cw_key_len;

static int      cw_wpm = 20;
static uint32_t cw_dit_samples = 48000 * 12 / (10 * 20);

static int      cw_unit;            /* index into cw_key */
static uint32_t cw_tick;            /* samples into the current unit */
static float    cw_env;             /* shaped envelope, 0..1 */
static int      cw_ramp;            /* position within an edge */

/* CAT "KY;"-triggered one-shot send (see cw_set_message()): unlike the
   looping beacon (plain "tx"/CAT "TX;", unchanged), a KY-triggered
   message should auto-return to RX after one pass. cw_msg_wrapped is set
   by cw_tx_process_block() when cw_key[] wraps back to 0 during a
   one-shot send; cw_keyer_poll() (main-loop rate, same place PTT-style
   session control already lives) acts on it. Deliberately not checked
   during live keying (cw_tx_source_live) - the two are mutually
   exclusive in practice (KY never sets cw_tx_source_live, the live
   paddle never sets cw_msg_oneshot). */
static volatile int cw_msg_oneshot;
static volatile int cw_msg_wrapped;

static float    cw_osc_re = 1.0f, cw_osc_im = 0.0f;
static float    cw_step_re, cw_step_im;

/* Sidetone oscillator: same envelope, but at cw_pitch_hz alone (no +12000 IF
   offset) since this drives the speaker directly, not an IF stage. */
static float    cw_side_re = 1.0f, cw_side_im = 0.0f;
static float    cw_side_step_re, cw_side_step_im;

/*
 * Live key/paddle input - an alternative to the beacon message above, not
 * a replacement: the console "tx"/CAT "TX;" commands still send CW_MSG as
 * before (useful for RF bench testing with no key connected), while
 * physically pressing a key/paddle starts and ends its own TX session and
 * keys live. cw_tx_process_block() below picks whichever source is active
 * per TX session (cw_tx_source_live) - both feed the exact same envelope/
 * oscillator code, since that part was already a live-updatable "want"
 * gate under the hood, just fed from cw_key[] until now.
 *
 * Menu-selectable key type (see hmi.c's FOCUS_KEYTYPE), matching the
 * convention on rigs like Oystein's FT-857D: Straight key needs no state
 * machine at all (want == key down, timing is entirely the operator's
 * hand). Iambic A/B run a classic squeeze keyer: while sending an
 * element, the opposite paddle being pressed latches "memory" so it
 * alternates automatically; the two modes differ only in what happens
 * right as both paddles release - mode A stops as soon as they're up,
 * mode B still sends one queued memory element first. This is the one
 * well-known, well-documented distinguishing behavior between the two
 * modes; the exact edge-case feel (as with any keyer) really wants a
 * real paddle to confirm against - untested on real hardware since none
 * exists yet, only bench-testable with two spare GPIOs/pushbuttons.
 */
typedef enum { CW_KEYER_STRAIGHT = 0, CW_KEYER_IAMBIC_A, CW_KEYER_IAMBIC_B } cw_keyer_type_t;
static cw_keyer_type_t cw_keyer_type = CW_KEYER_STRAIGHT;

int cw_keyer_type_get(void) { return (int)cw_keyer_type; }

void cw_keyer_type_set(int t)
{
    if (t >= CW_KEYER_STRAIGHT && t <= CW_KEYER_IAMBIC_B)
        cw_keyer_type = (cw_keyer_type_t)t;
}

const char *cw_keyer_type_name(void)
{
    static const char *names[] = { "STRAIGHT", "IAMBIC-A", "IAMBIC-B" };
    return names[cw_keyer_type];
}

/* 1 when the current TX session was started by the physical key/paddle
   (cw_keyer_poll(), below) rather than by the console/CAT beacon TX
   command - tells cw_tx_process_block() which source feeds "want". */
static int cw_tx_source_live;

typedef enum { CW_KEYER_IDLE, CW_KEYER_SEND_DIT, CW_KEYER_SEND_DAH, CW_KEYER_SPACE } cw_keyer_state_t;
static cw_keyer_state_t cw_keyer_state;
static uint32_t cw_keyer_timer;
static uint8_t  cw_keyer_dit_mem;
static uint8_t  cw_keyer_dah_mem;
static uint8_t  cw_keyer_last_was_dit;

/* Sample-rate (called once per audio sample from cw_tx_process_block(),
   same cadence as the cw_key[] array lookup it replaces) - returns the
   live "want" gate: 1 = key down / element being sent, 0 = up/space. */
static int cw_keyer_tick(void)
{
    uint8_t dit = cw_paddle_dit_read();
    uint8_t dah = (cw_keyer_type != CW_KEYER_STRAIGHT) ? cw_paddle_dah_read() : 0U;

    if (cw_keyer_type == CW_KEYER_STRAIGHT)
        return dit;

    switch (cw_keyer_state)
    {
    case CW_KEYER_IDLE:
        cw_keyer_dit_mem = 0;
        cw_keyer_dah_mem = 0;
        if (dit)
        {
            cw_keyer_state = CW_KEYER_SEND_DIT;
            cw_keyer_timer = cw_dit_samples;
            cw_keyer_last_was_dit = 1;
        }
        else if (dah)
        {
            cw_keyer_state = CW_KEYER_SEND_DAH;
            cw_keyer_timer = cw_dit_samples * 3U;
            cw_keyer_last_was_dit = 0;
        }
        return 0;

    case CW_KEYER_SEND_DIT:
    case CW_KEYER_SEND_DAH:
        if (dit) cw_keyer_dit_mem = 1;
        if (dah) cw_keyer_dah_mem = 1;
        if (--cw_keyer_timer == 0U)
        {
            cw_keyer_state = CW_KEYER_SPACE;
            cw_keyer_timer = cw_dit_samples;   /* one dit of inter-element space */
        }
        return 1;

    case CW_KEYER_SPACE:
    default:
        if (dit) cw_keyer_dit_mem = 1;
        if (dah) cw_keyer_dah_mem = 1;
        if (--cw_keyer_timer != 0U)
            return 0;

        if (!dit && !dah && cw_keyer_type == CW_KEYER_IAMBIC_A)
        {
            /* Mode A: no bonus element once both paddles are actually up. */
            cw_keyer_state = CW_KEYER_IDLE;
            return 0;
        }

        /* Alternate first (squeeze, or - mode B only - one bonus element
           right after release via memory); otherwise repeat whichever
           paddle is still physically held; otherwise stop. */
        if (!cw_keyer_last_was_dit && (dit || cw_keyer_dit_mem))
        {
            cw_keyer_state = CW_KEYER_SEND_DIT;
            cw_keyer_timer = cw_dit_samples;
            cw_keyer_last_was_dit = 1;
        }
        else if (cw_keyer_last_was_dit && (dah || cw_keyer_dah_mem))
        {
            cw_keyer_state = CW_KEYER_SEND_DAH;
            cw_keyer_timer = cw_dit_samples * 3U;
            cw_keyer_last_was_dit = 0;
        }
        else if (dit)
        {
            cw_keyer_state = CW_KEYER_SEND_DIT;
            cw_keyer_timer = cw_dit_samples;
            cw_keyer_last_was_dit = 1;
        }
        else if (dah)
        {
            cw_keyer_state = CW_KEYER_SEND_DAH;
            cw_keyer_timer = cw_dit_samples * 3U;
            cw_keyer_last_was_dit = 0;
        }
        else
        {
            cw_keyer_state = CW_KEYER_IDLE;
        }

        if (cw_keyer_state != CW_KEYER_IDLE)
        {
            cw_keyer_dit_mem = 0;
            cw_keyer_dah_mem = 0;
        }
        return 0;
    }
}

/*
 * Message text: was a fixed CW_MSG #define (a beacon, sent on plain
 * "tx"/CAT "TX;", loops forever - unchanged default behavior, see
 * cw_tx_process_block()). Now also settable at runtime via the CAT "KY;"
 * command (real Kenwood's actual "send this text now via the keyer"
 * command - kept for familiarity, and because it happens to be exactly
 * what's needed here) and Hamlib's send_morse() hook. Setting via KY;
 * additionally triggers a ONE-SHOT send (cw_msg_oneshot below) that
 * auto-returns to RX after one pass, unlike the looping beacon - see
 * cw_keyer_poll()'s completion check. */
static char cw_msg[CW_MSG_MAXLEN + 1] = CW_MSG_DEFAULT;

void cw_set_message(const char *text)
{
    size_t i;

    for (i = 0; i < CW_MSG_MAXLEN && text[i]; i++)
    {
        char c = text[i];
        if (c >= 'a' && c <= 'z') c -= 32;  /* cw_morse()'s table is A-Z only */
        cw_msg[i] = c;
    }
    cw_msg[i] = 0;

    cw_key_len = 0;   /* force cw_build_message() to rebuild from the new
                          text - it's normally built once, lazily, and
                          cached forever (see cw_tx_restart()) */
}

const char *cw_get_message(void) { return cw_msg; }

static void cw_build_message(void)
{
    int n = 0;

    for (const char *p = cw_msg; *p; p++)
    {
        if (*p == ' ')
        {
            /* Word gap is 7 units; 3 were already emitted after the letter. */
            for (int i = 0; i < 4 && n < CW_UNITS; i++) cw_key[n++] = 0;
            continue;
        }

        for (const char *e = cw_morse(*p); *e; e++)
        {
            int len = (*e == '-') ? 3 : 1;

            for (int i = 0; i < len && n < CW_UNITS; i++) cw_key[n++] = 1;
            if (n < CW_UNITS) cw_key[n++] = 0;          /* inter-element gap */
        }

        for (int i = 0; i < 2 && n < CW_UNITS; i++) cw_key[n++] = 0;  /* -> 3 */
    }

    for (int i = 0; i < 7 && n < CW_UNITS; i++) cw_key[n++] = 0;      /* tail */

    cw_key_len = n;
}

void cw_set_wpm(int wpm)
{
    cw_wpm = wpm;
    cw_dit_samples = (uint32_t)(48000.0f * 1.2f / (float)wpm);
}

int cw_get_wpm(void) { return cw_wpm; }

void cw_tx_restart(void)
{
    if (!cw_key_len) cw_build_message();

    cw_unit = 0;
    cw_tick = 0;
    cw_env  = 0.0f;
    cw_ramp = 0;

    /* Carrier at the IF centre plus the tone pitch, same as receive expects.
       Runtime cw_pitch_hz, not the old fixed CW_PITCH_HZ, so a pitch change
       moves the TX carrier and the RX filter together. */
    float dphi = 2.0f * (float)M_PI * (12000.0f + cw_pitch_hz) / 48000.0f;

    cw_step_re = cosf(dphi);
    cw_step_im = sinf(dphi);
    cw_osc_re  = 1.0f;
    cw_osc_im  = 0.0f;

    float dphi_side = 2.0f * (float)M_PI * cw_pitch_hz / 48000.0f;
    cw_side_step_re = cosf(dphi_side);
    cw_side_step_im = sinf(dphi_side);
    cw_side_re = 1.0f;
    cw_side_im = 0.0f;
}

void cw_tx_process_block(uint16_t *out, uint16_t *side_out, int n)
{
    for (int i = 0; i < n; i++)
    {
        /* Live key/paddle session: want comes from the real-time keyer,
           sampled fresh every sample - the beacon array below still
           advances underneath it (harmless; cw_tx_restart() always resets
           it at the start of the next session regardless of source) but
           isn't what's actually keying the carrier. */
        int want = cw_tx_source_live ? cw_keyer_tick() : cw_key[cw_unit];

        if (++cw_tick >= cw_dit_samples)
        {
            cw_tick = 0;
            if (++cw_unit >= cw_key_len)
            {
                cw_unit = 0;
                if (!cw_tx_source_live && cw_msg_oneshot) cw_msg_wrapped = 1;
            }
        }

        /* Raised-cosine edge, so the spectrum stays where it belongs. */
        if (want && cw_ramp < CW_RAMP) cw_ramp++;
        else if (!want && cw_ramp > 0) cw_ramp--;

        cw_env = 0.5f * (1.0f - cosf((float)M_PI * (float)cw_ramp / (float)CW_RAMP));

        float y = cw_env * cw_osc_re * 1800.0f + 2048.0f;

        float nre = cw_osc_re * cw_step_re - cw_osc_im * cw_step_im;
        float nim = cw_osc_re * cw_step_im + cw_osc_im * cw_step_re;
        float g   = 1.5f - 0.5f * (nre * nre + nim * nim);

        cw_osc_re = nre * g;
        cw_osc_im = nim * g;

        if (y < 0.0f)    y = 0.0f;
        if (y > 4095.0f) y = 4095.0f;

        out[i] = (uint16_t)y;

        /* Same envelope, same edge timing, just at the audio pitch instead
           of the IF carrier - so sidetone keying matches the actual
           transmitted envelope exactly, not a separately-timed copy. */
        float ys = cw_env * cw_side_re * 1800.0f + 2048.0f;

        float snre = cw_side_re * cw_side_step_re - cw_side_im * cw_side_step_im;
        float snim = cw_side_re * cw_side_step_im + cw_side_im * cw_side_step_re;
        float sg   = 1.5f - 0.5f * (snre * snre + snim * snim);

        cw_side_re = snre * sg;
        cw_side_im = snim * sg;

        if (ys < 0.0f)    ys = 0.0f;
        if (ys > 4095.0f) ys = 4095.0f;

        side_out[i] = (uint16_t)ys;
    }
}

/* Forward declarations: radio_tx_on()/radio_tx_off() (defined further down
   with the rest of the console/CAT-shared TX control functions) - needed
   here so cw_keyer_poll() can start/stop its own TX session the same way
   PTT and the console/CAT "tx"/"rx" commands already do. */
int  radio_tx_on(void);
void radio_tx_off(void);

/*
 * Main-loop-rate (not sample-rate) polling for the physical key/paddle -
 * decides when a live-keyed TX session should start and end, the same
 * coarse "session" role PTT plays for voice modes. Deliberately NOT
 * sample-rate: radio_tx_on()/radio_tx_off() reset DMA/USB audio rings and
 * are far too expensive to call more than once per over. The actual
 * element-by-element keying happens separately, at sample rate, in
 * cw_keyer_tick() inside cw_tx_process_block() above.
 */
/* How long the key/paddle can sit idle mid-session before TX drops.
   MUST scale with WPM, not be a fixed duration: a normal inter-word gap
   is 7 dit-units, which at the default 20 WPM alone is already 420 ms -
   a fixed 300 ms (the original value here) dropped TX, and paid the full
   radio_tx_on()/DMA-reset cost, between every single word, which is
   exactly the "feels slow" Oystein hit testing with jumper wires. 10 dit
   units gives clear margin over the 7-unit word gap at any speed, while
   still ending a genuinely-finished over reasonably promptly - and
   because it's dit-unit-based, it stays correct automatically as WPM
   (cw_dit_samples) changes, instead of needing retuning per speed. */
#define CW_KEYER_HANG_DIT_UNITS 10U

void cw_keyer_poll(void)
{
    static uint32_t last_active_tick;

    if (MODE != MODE_CW)
        return;

    /* KY-triggered one-shot message finished its one pass - auto-return
       to RX, unlike the looping beacon. Checked here since this already
       runs every main-loop iteration while in CW mode. */
    if (cw_msg_oneshot && cw_msg_wrapped)
    {
        radio_tx_off();
    }

    uint8_t active = cw_paddle_dit_read()
                    || (cw_keyer_type != CW_KEYER_STRAIGHT && cw_paddle_dah_read());
    uint32_t now = HAL_GetTick();
    uint32_t hang_ms = (cw_dit_samples * CW_KEYER_HANG_DIT_UNITS) / 48U;  /* samples -> ms at 48 kHz */

    if (active)
    {
        last_active_tick = now;
        if (!tx_active)
        {
            cw_tx_source_live = 1;
            radio_tx_on();
        }
    }
    else if (tx_active && cw_tx_source_live && (now - last_active_tick) >= hang_ms)
    {
        radio_tx_off();   /* clears cw_tx_source_live itself */
    }
}

/*
 * FreeDV transmit.
 *
 * The microphone goes into codec2, and what comes back is a modem waveform
 * that still has to be put on the air by one of the analog modulators: 1600,
 * 700D and 700E ride on SSB, 2400B on FM. So this is the vocoder and modem in
 * front of the modulators, not a modulator of its own.
 *
 * Note what is deliberately absent: no speech band pass, no microphone gain,
 * no compression on the modem waveform. Those belong to voice. Applying them
 * to a modem signal distorts the very thing the far end has to demodulate,
 * which is why FreeDV operating tells you to set drive by peak and leave ALC
 * out of it.
 */
/*
 * Feed one block of microphone audio into the FreeDV chain (decimate only).
 * The encode is separate, so this stays cheap and can run every block.
 */
void freedv_tx_feed(const uint16_t *in, int n)
{
    float *audio = &dsp_scratch[0 * SCRATCH_N];
    float  peak  = 0.0f;

    for (int i = 0; i < n; i++)
    {
        float x = ((float)(in[i] & 0x0FFF) - 2048.0f) / 2048.0f;

        float a = fabsf(x);
        if (a > peak) peak = a;

        audio[i] = x * mic_gain;        /* gain on speech, before codec2 */
    }

    rx_adc_peak = peak;
    rx_blocks++;

    if (freedv_ok) freedv_chain_put_speech48(audio, n);
}

/*
 * Produce one block of modem IF into the DAC. Pulls interpolated modem samples
 * and runs them through the SSB or FM modulator. Cheap -- no encode here.
 */
void freedv_tx_produce(uint16_t *out, int n)
{
    float *audio = &dsp_scratch[0 * SCRATCH_N];
    float *q     = &dsp_scratch[1 * SCRATCH_N];

    if (!freedv_ok)
    {
        for (int i = 0; i < n; i++) out[i] = DAC_MID;
        return;
    }

    freedv_chain_get_modem48(audio, n);     /* modem waveform, not speech */

    float mpk = 0.0f;
    for (int i = 0; i < n; i++)
    {
        float a = fabsf(audio[i]);
        if (a > mpk) mpk = a;
    }
    rx_peak = mpk;                          /* modem drive level */

    if (MODE == MODE_FREEDV_2400B)
    {
        fm_modulate(audio, out, n, 2500.0f);   /* what 2400B expects */
    }
    else
    {
        ssb_hilbert(audio, q, n);
        ssb_modulate(audio, q, out, n, 0);  /* FreeDV rides on USB */
    }
}

/*
 * AM transmit.
 *
 * Amplitude modulation is a carrier plus the audio riding on it: the envelope
 * is (1 + m*audio) and that multiplies a cos at the IF. Unlike SSB there is no
 * Hilbert and no sideband selection -- both sidebands are sent, symmetric
 * about the carrier -- so this is simpler than the SSB modulator, not harder.
 *
 * The modulation index m is kept a little under 1 so the envelope never
 * reaches zero; at m = 1 it just touches zero (100 %), and above that it would
 * go negative and distort, exactly the over-modulation the receiver side
 * showed. Mic gain sets the drive into it.
 */
void am_tx_process_block(const uint16_t *in, uint16_t *out, int n)
{
    float *audio = &dsp_scratch[0 * SCRATCH_N];

    float peak = 0.0f;

    if (am_testtone)
    {
        /* Fixed internal 1 kHz tone at 50% depth -- removes the mic entirely,
           so a clean AM signal here proves the modulator. */
        static float ph = 0.0f;
        const float dph = 2.0f * (float)M_PI * 1000.0f / 48000.0f;

        for (int i = 0; i < n; i++)
        {
            audio[i] = 0.85f * cosf(ph);   /* ~80%% modulation depth */
            ph += dph;
            if (ph > 2.0f * (float)M_PI) ph -= 2.0f * (float)M_PI;
        }
        rx_adc_peak = 0.85f;
    }
    else
    {
        for (int i = 0; i < n; i++)
        {
            float x = ((float)(in[i] & 0x0FFF) - 2048.0f) / 2048.0f;

            float a = fabsf(x);
            if (a > peak) peak = a;

            audio[i] = x * mic_gain;
        }

        rx_adc_peak = peak;

        /* Speech band limiting, reusing the SSB audio filter. */
        arm_biquad_cascade_df1_f32(&ssb_audio, audio, audio, n);
    }

    rx_blocks++;

    const float m = 0.95f;      /* keep the envelope non-negative */

    float mpk = 0.0f;

    for (int i = 0; i < n; i++)
    {
        float env = 1.0f + m * audio[i];

        if (env < 0.0f) env = 0.0f;              /* no over-modulation */
        if (env > mpk)  mpk  = env;

        float carrier = ssb_osc_re;              /* cos at the IF */

        float nre = ssb_osc_re * ssb_step_re - ssb_osc_im * ssb_step_im;
        float nim = ssb_osc_re * ssb_step_im + ssb_osc_im * ssb_step_re;
        float g   = 1.5f - 0.5f * (nre * nre + nim * nim);

        ssb_osc_re = nre * g;
        ssb_osc_im = nim * g;

        /* 1000 is about the ceiling: full modulation takes the envelope to ~2x
           the carrier, so 2 * 1000 fits the 2048 DAC half-swing. */
        float y = env * carrier * 1000.0f + 2048.0f;

        if (y < 0.0f)    y = 0.0f;
        if (y > 4095.0f) y = 4095.0f;

        out[i] = (uint16_t)y;
    }

    rx_peak = mpk;                                /* peak envelope */
}

/*
 * Transmit dispatch. CW keys its own carrier and takes no input; the voice
 * modes modulate whatever is on the microphone ADC. side_out is the CW
 * sidetone buffer - only CW writes it, since it's the only TX mode DAC1
 * stays running for (see audio_dma_start()).
 */
static void tx_process_block(const uint16_t *in, uint16_t *out, uint16_t *side_out, int n)
{
    if (MODE == MODE_CW)                            cw_tx_process_block(out, side_out, n);
    else if (MODE == MODE_USB || MODE == MODE_LSB)  ssb_tx_process_block(in, out, n);
    else if (MODE == MODE_NBFM)                     nbfm_tx_process_block(in, out, n);
    else if (MODE == MODE_AM)                       am_tx_process_block(in, out, n);
    else
    {
        for (int i = 0; i < n; i++) out[i] = 2048;  /* nothing to send yet */
    }
}

static int tx_supported(int mode)
{
    return mode == MODE_CW || mode == MODE_USB || mode == MODE_LSB
        || mode == MODE_NBFM || mode == MODE_AM || mode_is_freedv(mode);
}

/*
 * Shared by the console's tx/rx commands and the HMI's PTT input (hmi.c),
 * so both paths key the radio exactly the same way rather than risking the
 * two drifting apart. Returns 0 if the current mode has no modulator yet.
 */
extern volatile int tx_rearm;

int radio_tx_on(void)
{
    if (!tx_supported(MODE))
        return 0;

    if (MODE == MODE_CW) cw_tx_restart();
    else                 ssb_tx_restart();  /* also inits the AM carrier osc */

    if (mode_is_freedv(MODE) && freedv_ok) freedv_chain_set_tx(1);

    tx_rearm  = 1;
    tx_active = 1;
    /* Nothing drains the USB speaker ring while receiving, so it holds
       stale audio (and a read pointer left wherever the last transmission
       stopped) by now - start this one from a clean cushion. Mic (IN) gets
       the same treatment: usb_audio_rx_capture() (RX) and
       usb_audio_mic_tx_update() (TX) are different producers with
       different cadences, and this is the one transition that swaps
       between them on every single PTT press - the biggest cadence change
       the mic ring's underrun guard has to absorb, so it's the one most
       worth starting clean rather than leaving to recover on its own. */
    USBD_AUDIO_DUPLEX_ResetSpeaker(&hUsbDeviceFS);
    USBD_AUDIO_DUPLEX_ResetMic(&hUsbDeviceFS);
    /* radio_set_mode() already does this when switching modes, but not
       here - and the RX front end (Hilbert transform, NCO, pre-demod
       filters in dsp_filters_init()) is shared across every mode, not
       mode-specific, so a plain RX/TX switch left it just as able to
       carry state across the ADC restart below as a mode switch would.
       Cheap to call unconditionally like the resets above. */
    dsp_filters_init();
    audio_dma_restart();  /* mic-in ADC / IF-out DAC, deep ring if buffered */
    HAL_GPIO_WritePin(LD3_GPIO_Port, LD3_Pin, GPIO_PIN_SET);
    return 1;
}

void radio_tx_off(void)
{
    tx_active = 0;
    cw_tx_source_live = 0;   /* defensive reset - every path that stops TX
                                 (console/CAT "rx", HMI PTT/TUNE release,
                                 the KY one-shot completion check) should
                                 leave these clean for the next session,
                                 not just the paths that happened to set
                                 them */
    cw_msg_oneshot = 0;
    cw_msg_wrapped = 0;
    if (mode_is_freedv(MODE) && freedv_ok) freedv_chain_set_tx(0);
    USBD_AUDIO_DUPLEX_ResetMic(&hUsbDeviceFS);  /* same reasoning as radio_tx_on() - back to usb_audio_rx_capture() as the producer now */
    dsp_filters_init();    /* see radio_tx_on() - same gap, same fix */
    audio_dma_restart();   /* back to IF-in ADC / audio-out DAC */
    HAL_GPIO_WritePin(LD3_GPIO_Port, LD3_Pin, GPIO_PIN_RESET);
}

/* ------------------------------------------------------------------------
 * UART console
 *
 * Exists so mode changes, PTT and levels can be driven over the ST-Link VCP
 * instead of by reflashing. A front panel comes later; putting the control
 * layer in first means the OLED and switches become a second way to reach
 * commands that already work, rather than a second thing to debug at the same
 * time as transmit.
 * --------------------------------------------------------------------- */

volatile int tx_active = 0;      /* set by ptt/tx, cleared by rx */
volatile int tx_rearm  = 1;      /* re-align the TX mic read on each PTT */
volatile int am_testtone = 0;    /* AM: modulate an internal 1 kHz tone, not the mic */

static char cons_line[64];
static int  cons_len;

static char cat_line[64];
static int  cat_len;

static int str_eq(const char *a, const char *b)
{
    while (*a && *b && *a == *b) { a++; b++; }
    return *a == 0 && *b == 0;
}

static int str_num(const char *s, int *out)
{
    int v = 0, any = 0;
    while (*s >= '0' && *s <= '9') { v = v * 10 + (*s++ - '0'); any = 1; }
    return any ? (*out = v, 1) : 0;
}

static void console_help(void)
{
    uart_puts("\r\ncommands:\r\n"
              "  mode          list modes\r\n"
              "  mode <n>      select mode by number\r\n"
              "  tx            key the CW beacon\r\n"
              "  rx            back to receive\r\n"
              "  mic <n>       microphone gain, 1..200\r\n"
              "  src [usb|analog]  audio routing: USB Audio class vs ADC/DAC pins\r\n"
              "  tone          toggle firmware 1 kHz sine into the USB TX path (diagnostic)\r\n"
              "  amtone        toggle AM 1 kHz test tone (50%%)\r\n"
              "  debug [on|off] toggle continuous telemetry\r\n"
              "  wpm <n>       CW speed\r\n"
              "  stat          current state\r\n"
              "  enc           encoder pin levels + count (HMI bring-up)\r\n"
              "  btn           button states 1..10, '1'=pressed (HMI bring-up)\r\n");
}

static void console_modes(void)
{
    uart_puts("\r\n");
    for (int i = 0; i < MODE_COUNT; i++)
    {
        if (mode_cfg[i].name == NULL) continue;
        uart_kv("", i);
        uart_puts(mode_cfg[i].name);
        uart_puts(i == MODE ? "   <= current\r\n" : "\r\n");
    }
}

static void console_exec(char *line)
{
    char *arg = line;

    while (*arg && *arg != ' ') arg++;
    if (*arg == ' ') *arg++ = 0;

    if (str_eq(line, "help") || str_eq(line, "?"))
    {
        console_help();
    }
    else if (str_eq(line, "mode"))
    {
        int n;
        if (str_num(arg, &n) && n >= 0 && n < MODE_COUNT && mode_cfg[n].name)
        {
            tx_active = 0;
            radio_set_mode(n);
            uart_puts("mode: ");
            uart_puts(mode_name(n));
            uart_puts("\r\n");
        }
        else console_modes();
    }
    else if (str_eq(line, "tx"))
    {
        if (!radio_tx_on())
        {
            uart_puts("no modulator for this mode yet\r\n");
        }
        else
        {
            uart_puts("tx: ");
            uart_puts(mode_name(MODE));
            uart_puts("\r\n");
        }
    }
    else if (str_eq(line, "rx"))
    {
        radio_tx_off();
        uart_puts("rx\r\n");
    }
    else if (str_eq(line, "debug"))
    {
        if      (str_eq(arg, "on"))  debug_on = 1;
        else if (str_eq(arg, "off")) debug_on = 0;
        else                         debug_on = !debug_on;
        uart_puts(debug_on ? "debug telemetry ON\r\n" : "debug telemetry off\r\n");
    }
    else if (str_eq(line, "amtone"))
    {
        am_testtone = !am_testtone;
        uart_puts(am_testtone ? "AM test tone ON (1 kHz, 50%)\r\n"
                              : "AM test tone off\r\n");
    }
    else if (str_eq(line, "mic"))
    {
        int n;
        if (str_num(arg, &n) && n >= 1 && n <= 200)
        {
            mic_gain = (float)n;
            uart_kv("mic gain", n);
            uart_puts("\r\n");
        }
        else uart_puts("mic 1..200\r\n");
    }
    else if (str_eq(line, "src"))
    {
        if (str_eq(arg, "usb"))         audio_source_set(AUDIO_SRC_USB);
        else if (str_eq(arg, "analog")) audio_source_set(AUDIO_SRC_ANALOG);
        else if (*arg)                  { uart_puts("src usb|analog\r\n"); return; }
        else audio_source_toggle();
        uart_puts(audio_source == AUDIO_SRC_USB ? "audio src: USB\r\n" : "audio src: analog (ADC/DAC)\r\n");
    }
    else if (str_eq(line, "tone"))
    {
        extern volatile int usb_tx_testtone;
        usb_tx_testtone = !usb_tx_testtone;
        uart_puts(usb_tx_testtone
                  ? "USB TX test tone ON - modulating a firmware 1 kHz sine, USB audio ignored\r\n"
                  : "USB TX test tone off - back to real USB audio\r\n");
    }
    else if (str_eq(line, "wpm"))
    {
        int n;
        if (str_num(arg, &n) && n >= 5 && n <= 60) { cw_set_wpm(n); uart_kv("wpm", n); uart_puts("\r\n"); }
        else uart_puts("wpm 5..60\r\n");
    }
    else if (str_eq(line, "stat"))
    {
        uart_puts("\r\nmode: ");
        uart_puts(mode_name(MODE));
        uart_kv("  tx", tx_active);
        uart_kv("wpm", cw_get_wpm());
        uart_kv("mic", (int)mic_gain);
        uart_kv("block", (int)block_size / 2);
        uart_puts("\r\n");
    }
    else if (str_eq(line, "enc"))
    {
        // Diagnostic for the encoder bring-up test: raw pin levels plus the
        // decoded count, so a wiring problem (stuck level, swapped A/B, no
        // common-to-GND) is visible directly rather than guessed at.
        int a = HAL_GPIO_ReadPin(GPIOB, GPIO_PIN_4) == GPIO_PIN_SET;
        int b = HAL_GPIO_ReadPin(GPIOB, GPIO_PIN_5) == GPIO_PIN_SET;
        uart_kv("\r\nenc A", a);
        uart_kv("B", b);
        uart_kv("count", (int)encoder_poll());
        uart_puts("\r\n");
    }
    else if (str_eq(line, "btn"))
    {
        // Diagnostic for the button bring-up test: one char per button,
        // position i = button i+1, '1' means pressed right now.
        uint16_t mask = buttons_read();
        char bits[BUTTON_COUNT + 1];
        for (int i = 0; i < BUTTON_COUNT; i++)
            bits[i] = (mask & (1u << i)) ? '1' : '0';
        bits[BUTTON_COUNT] = 0;
        uart_puts("\r\nbtn 1..10: ");
        uart_puts(bits);
        uart_puts("\r\n");
    }
    else if (*line)
    {
        uart_puts("? try help\r\n");
    }
}

static void console_poll(void)
{
    if (!(huart3.Instance->ISR & USART_ISR_RXNE))
        return;

    char c = (char)(huart3.Instance->RDR & 0xFF);

    if (c == '\r' || c == '\n')
    {
        uart_puts("\r\n");
        cons_line[cons_len] = 0;
        console_exec(cons_line);
        cons_len = 0;
        uart_puts("> ");
    }
    else if ((c == 8 || c == 127) && cons_len)
    {
        cons_len--;
        uart_puts("\b \b");
    }
    else if (c >= ' ' && cons_len < (int)sizeof(cons_line) - 1)
    {
        cons_line[cons_len++] = c;
        char e[2] = { c, 0 };
        uart_puts(e);
    }
}

/* CAT control: a small subset of Kenwood-flavored ASCII commands, our own
   design (not byte-exact to any real rig's spec - see usbd_audio_duplex.h's
   header comment and the CAT plan for why). Framing: a line is terminated
   by '\r'/'\n' same as the debug console, and each command's payload is
   conventionally ';'-terminated too (trimmed below) purely for Kenwood
   flavor - the '\n' is what actually triggers dispatch.

   MD;/MDx;   - get/set mode (Kenwood digit table: 1=LSB 2=USB 3=CW 4=FM
                5=AM; FreeDV modes report '2' on GET, have no SET mapping)
   FA;/FB;    - get VFO frequency (11-digit Hz), FA<digits>;/FB<digits>; sets
                it - cosmetic only, backed by hmi.c's UI-only vfo_freq_hz,
                does not tune anything real (no LO hardware exists yet)
   TX;/RX;    - PTT on/off, no reply either way (matches real Kenwood's
                fire-and-forget convention)
   IF;        - compact custom status: "IF" + 11-digit freq + mode digit +
                PTT digit ('1'=TX/'0'=RX) + ";" - NOT real Kenwood's 38-byte
                IF; layout, see the CAT plan for why that's unnecessary here
   ID;        - fixed reply, lets a Hamlib open() sequence complete quickly
   MG;/MGnnn; - get/set mic gain, 3 digits, range 1-200 (same as the
                console's "mic <n>"; real Kenwood MG is 0-100, ours isn't
                spec-bound so it keeps this project's own existing range)
   KS;/KSnn;  - get/set CW keying speed (WPM), 2 digits, range 5-60 (same
                as the console's "wpm <n>"; digit count matches real
                Kenwood's KS, chosen for familiarity, not required)
   PT;/PTnnnn;- get/set CW sidetone/RX pitch in Hz, 4 digits, range
                300-1000 (cw_set_pitch() already clamps to this - no real
                Kenwood equivalent, this project's own command)
   AS;/AS0;/AS1; - get/set audio source, 0=analog ADC/DAC, 1=USB (same as
                the console's "src usb|analog"; no real Kenwood equivalent,
                this bench setup's own concept)

   Replies go out via cat_puts(), never uart_puts() - the transport fix
   this replaces the old console_exec()-forwarding stub with. */

static const char mode_kw_get[MODE_COUNT] = {
    [MODE_NBFM]         = '4',
    [MODE_USB]          = '2',
    [MODE_LSB]          = '1',
    [MODE_FREEDV]       = '2',
    [MODE_FREEDV_2400B] = '2',
    [MODE_FREEDV_700D]  = '2',
    [MODE_FREEDV_700E]  = '2',
    [MODE_AM]           = '5',
    [MODE_CW]           = '3',
};

static int kw_to_mode(char c)
{
    switch (c)
    {
        case '1': return MODE_LSB;
        case '2': return MODE_USB;
        case '3': return MODE_CW;
        case '4': return MODE_NBFM;
        case '5': return MODE_AM;
        default:  return -1;
    }
}

void cat_puts(const char *s);

static void cat_exec(char *line)
{
    size_t len = strlen(line);
    char reply[48];   /* KY's reply is the longest: "KY" + up to CW_MSG_MAXLEN + ";\r\n" */

    if (len && line[len - 1] == ';')
        line[--len] = 0;

    if (len < 2)
        return;

    if (line[0] == 'M' && line[1] == 'D')
    {
        if (line[2] == 0)
        {
            snprintf(reply, sizeof(reply), "MD%c;\r\n", mode_kw_get[MODE]);
            cat_puts(reply);
        }
        else
        {
            int m = kw_to_mode(line[2]);
            if (m >= 0)
            {
                tx_active = 0;
                radio_set_mode(m);
            }
        }
    }
    else if (line[0] == 'F' && (line[1] == 'A' || line[1] == 'B'))
    {
        if (line[2] == 0)
        {
            snprintf(reply, sizeof(reply), "%c%c%011lu;\r\n",
                     line[0], line[1], (unsigned long)hmi_get_vfo_freq());
            cat_puts(reply);
        }
        else
        {
            hmi_set_vfo_freq((uint32_t)strtoul(&line[2], NULL, 10));
        }
    }
    else if (line[0] == 'T' && line[1] == 'X')
    {
        radio_tx_on();
    }
    else if (line[0] == 'R' && line[1] == 'X')
    {
        radio_tx_off();
    }
    else if (line[0] == 'K' && line[1] == 'Y')
    {
        if (line[2] == 0)
        {
            snprintf(reply, sizeof(reply), "KY%s;\r\n", cw_get_message());
            cat_puts(reply);
        }
        else
        {
            /* Real Kenwood's KY genuinely means "send this now", not just
               "remember this for later" - matched here since it's exactly
               what's needed: sets the message AND triggers a one-shot
               send, auto-returning to RX when done (unlike the looping
               beacon a bare TX; still sends, unchanged). radio_tx_on()
               is safe to call again mid-session - cw_tx_restart() resets
               cleanly every time, so re-sending KY while a previous one
               is still going just restarts fresh with the new text. */
            cw_set_message(&line[2]);
            cw_msg_oneshot = 1;
            cw_msg_wrapped = 0;
            radio_tx_on();
        }
    }
    else if (line[0] == 'I' && line[1] == 'F')
    {
        snprintf(reply, sizeof(reply), "IF%011lu%c%c;\r\n",
                 (unsigned long)hmi_get_vfo_freq(), mode_kw_get[MODE],
                 tx_active ? '1' : '0');
        cat_puts(reply);
    }
    else if (line[0] == 'I' && line[1] == 'D')
    {
        cat_puts("ID019;\r\n");
    }
    else if (line[0] == 'M' && line[1] == 'G')
    {
        if (line[2] == 0)
        {
            snprintf(reply, sizeof(reply), "MG%03d;\r\n", (int)mic_gain);
            cat_puts(reply);
        }
        else
        {
            int n = (int)strtol(&line[2], NULL, 10);
            if (n >= 1 && n <= 200)
                mic_gain = (float)n;
        }
    }
    else if (line[0] == 'K' && line[1] == 'S')
    {
        if (line[2] == 0)
        {
            snprintf(reply, sizeof(reply), "KS%02d;\r\n", cw_get_wpm());
            cat_puts(reply);
        }
        else
        {
            int n = (int)strtol(&line[2], NULL, 10);
            if (n >= 5 && n <= 60)
                cw_set_wpm(n);
        }
    }
    else if (line[0] == 'P' && line[1] == 'T')
    {
        if (line[2] == 0)
        {
            snprintf(reply, sizeof(reply), "PT%04d;\r\n", (int)cw_pitch_hz);
            cat_puts(reply);
        }
        else
        {
            /* cw_set_pitch() already clamps to 300-1000 Hz internally,
               same as the HMI encoder's own calls to it. */
            cw_set_pitch((float)strtol(&line[2], NULL, 10));
        }
    }
    else if (line[0] == 'A' && line[1] == 'S')
    {
        if (line[2] == 0)
        {
            snprintf(reply, sizeof(reply), "AS%d;\r\n", audio_source_is_usb() ? 1 : 0);
            cat_puts(reply);
        }
        else if (line[2] == '0')
        {
            audio_source_set(AUDIO_SRC_ANALOG);
        }
        else if (line[2] == '1')
        {
            audio_source_set(AUDIO_SRC_USB);
        }
    }
}

void cat_puts(const char *s)
{
    (void)USBD_AD_CDC_Write(&hUsbDeviceFS, (const uint8_t *)s, (uint32_t)strlen(s));
}

static void cat_poll(void)
{
    uint8_t c;

    USBD_AD_CDC_Poll(&hUsbDeviceFS);

    if (USBD_AD_CDC_Read(&hUsbDeviceFS, &c, 1U) == 0U)
        return;

    /* No local echo, no prompt, unlike console_poll() - a CAT client (a
       Hamlib backend, or rigctl) reads exactly the bytes cat_exec() sends
       as a reply and nothing else; echoing typed characters back would
       corrupt that framing (the echoed bytes have no way to be told apart
       from a real reply). A human testing this over a raw terminal will
       need local echo turned on in the terminal program itself instead -
       the same experience as testing a real Kenwood rig's CAT port. */
    if (c == '\r' || c == '\n')
    {
        cat_line[cat_len] = 0;
        cat_exec(cat_line);
        cat_len = 0;
    }
    else if ((c == 8 || c == 127) && cat_len)
    {
        cat_len--;
    }
    else if (c >= ' ' && cat_len < (int)sizeof(cat_line) - 1)
    {
        cat_line[cat_len++] = (char)c;
    }
}

void process_block(const uint16_t *in, uint16_t *out, int n)
{
    uint32_t t0 = DWT->CYCCNT;

    if (MODE == MODE_NBFM)
    {
        nbfm_process_block(in, out, n);
    }
    else if (MODE == MODE_FREEDV_2400B)
    {
        freedv2400b_process_block(in, out, n);  // FM-bane, ikke SSB
    }
    else if (MODE == MODE_AM)
    {
        am_process_block(in, out, n);           // egen bane, ingen Hilbert
    }
    else
    {
        ssb_process_block(in, out, n);  // din eksisterende SSB-pipe
    }

    uint32_t dt = DWT->CYCCNT - t0;
    if (dt > rx_cycles_max)
        rx_cycles_max = dt;
}

void nbfm_init(float if_freq_hz, float fs_hz)
{
    // NCO for IF-mixing
    nco_init(&nco_if, if_freq_hz, fs_hz);

    // Pre-demod IF-filter (bruk dine egne koeffisienter)
arm_fir_init_f32(&pre_fm_I,
                 PRE_DEMOD_TAPS,
                 pre_demod_coeffs,
                 pre_fm_state_I,
                 BLOCK_SIZE_MAX/2);

arm_fir_init_f32(&pre_fm_Q,
                 PRE_DEMOD_TAPS,
                 pre_demod_coeffs,
                 pre_fm_state_Q,
                 BLOCK_SIZE_MAX/2);

    // Audio LPF etter FM-demod
    arm_fir_init_f32(&audio_lpf,
                     AUDIO_TAPS,
                     audio_lpf_coeffs,
                     audio_state,
                     BLOCK_SIZE_ANALOG/2);
}

/* USER CODE END 0 */

int main(void)
{

  /* MPU Configuration--------------------------------------------------------*/
  MPU_Config();

  // At 216 MHz flash runs with 7 wait states, so without the instruction cache
  // every fetch stalls. Enabling it costs nothing in correctness (unlike the
  // D-cache, which would need coherency handling for the ADC/DAC DMA buffers)
  // and is worth several times the throughput on this DSP path.
  SCB_EnableICache();

  /* MCU Configuration--------------------------------------------------------*/

  /* Reset of all peripherals, Initializes the Flash interface and the Systick. */
  HAL_Init();

  /* Configure the system clock */
  SystemClock_Config();

  /* Initialize all configured peripherals */
  MX_GPIO_Init();
  MX_DMA_Init();
  MX_ETH_Init();
  MX_I2C1_Init();
  MX_USART3_UART_Init();
  MX_USB_OTG_FS_PCD_Init();
  MX_DAC_Init();
  MX_TIM6_Init();
  MX_ADC1_Init();
  MX_ADC2_Init();
  /* USER CODE BEGIN 2 */

  MX_USB_DEVICE_Init();

  /* Chasing small, regularly-spaced amplitude spikes heard only over
     audio:usb, in every mode, that a live radio_set_mode()/audio_source_set()
     call fixes *permanently* (confirmed: does not come back, so this isn't
     drift needing a periodic correction - something is wrong with the state
     boot alone reaches, corrected once a live switch runs). Two hand-picked
     boot-time replicas (dsp_filters_init()+audio_dma_start() alone, then
     +ResetSpeaker()/ResetMic() on top, both 2026-08-06) made no difference,
     so guessing at which piece(s) of a live switch matter isn't working -
     radio_apply_mode() is the exact body radio_set_mode() runs, extracted so
     boot can run the real thing unconditionally instead of a subset of it.
     ResetSpeaker() is added after it to also cover the one thing
     audio_source_set() does beyond that (radio_apply_mode() itself has no
     reason to touch the speaker/TX ring). */
  radio_apply_mode(MODE);
  USBD_AUDIO_DUPLEX_ResetSpeaker(&hUsbDeviceFS);

  //Start TIM6
  HAL_TIM_Base_Start(&htim6);

  // Brought up after the DMAs are running, and deliberately not fatal: if
  // codec2 cannot allocate we still want the radio and the UART alive so the
  // failure is visible instead of silently hanging the board.
  cyclecount_init();

  uart_puts("\r\n=== qrp-sdr-trx ===\r\n");

  uart_kv("heap_largest", (int)heap_largest_free());
  uart_puts("\r\n");

  freedv_ok = mode_is_freedv(MODE)
            ? (freedv_chain_init(chain_mode_for(MODE)) == 0)
            : 0;

  if (freedv_ok)
  {
      uart_puts("freedv: ");
      uart_puts(mode_name(MODE));
      uart_puts(" RX ready\r\n");
  }
  else if (mode_is_freedv(MODE))
  {
      uart_puts("freedv: init FAILED (out of heap?) - audio will be silent\r\n");
  }

  uart_kv("heap_left", (int)heap_largest_free());
  uart_puts("\r\ntype 'help' for commands\r\n> ");

  // Front panel: OLED + encoder + 10 buttons + PTT (USER_Btn on this test
  // board). See hmi.c for what's real (mode, PTT, mic gain) vs. still a UI
  // skeleton with no hardware behind it yet (freq, band, RIT, CW pitch,
  // volume).
  hmi_init(&hi2c1);
  cw_paddle_gpio_init();

  /* USER CODE END 2 */

  /* Infinite loop */
  /* USER CODE BEGIN WHILE */
  while (1)
  {

    uart_pump();
    console_poll();
    cat_poll();

    // Front panel: encoder, buttons, PTT, OLED redraw - see hmi.c. Rate
    // limiting and the non-blocking I2C push live there now too.
    hmi_poll();

    // Live CW key/paddle: session start/stop only (PTT-equivalent) - the
    // actual element timing happens at sample rate inside
    // cw_tx_process_block(), not here.
    cw_keyer_poll();

    if (tx_active)
    {
      uint32_t n = block_size / 2;

      if (mode_is_buffered(MODE))
      {
        /*
         * FreeDV transmit is decoupled from DAC timing. The mic is read from
         * the ADC ring following its write pointer; the encode (up to 53 ms for
         * 700E) runs here in the main loop; and the DAC is a deep circular
         * buffer the DMA plays through while we fill ahead of its read pointer.
         * A slow encode draws down the cushion instead of stalling the output.
         */
        static uint16_t tx_mic[BLOCK_SIZE_MAX / 2];
        static uint32_t tx_rd;    /* mic read pos in the ADC ring */
        static uint32_t dac_wr;   /* fill pos in the DAC ring */

        if (tx_rearm)
        {
          tx_rd    = (adc_dma_pos() + ADC_RING_LEN - 2 * n) % ADC_RING_LEN;
          dac_wr   = 0;
          tx_rearm = 0;
        }

        /* Feed every mic block the ADC has captured since last time. */
        while (((adc_dma_pos() + ADC_RING_LEN - tx_rd) % ADC_RING_LEN) >= n)
        {
          for (uint32_t i = 0; i < n; i++)
            tx_mic[i] = adc_buffer[(tx_rd + i) % ADC_RING_LEN];

          if (audio_source == AUDIO_SRC_USB)
          {
              int16_t pcm[BLOCK_SIZE_MAX / 2];
              USBD_AUDIO_DUPLEX_GetSpeakerAudio(&hUsbDeviceFS, pcm, n);
              for (uint32_t i = 0; i < n; i++)
                  tx_mic[i] = pcm16_to_sample(pcm[i]);
          }

          tx_rd = (tx_rd + n) % ADC_RING_LEN;
          freedv_tx_feed(tx_mic, n);
        }

        /* Encode ahead -- this is the heavy, bursty part. */
        {
          uint32_t te = DWT->CYCCNT;
          freedv_chain_encode();
          uint32_t enc = DWT->CYCCNT - te;
          if (enc > rx_adc_cycles) rx_adc_cycles = enc;
        }

        /* Fill the DAC ahead of where the DMA is reading. */
        {
          uint32_t play  = dac_dma_pos();
          uint32_t ahead = (dac_wr + DAC_RING_LEN - play) % DAC_RING_LEN;

          if (ahead < tx_cushion_min) tx_cushion_min = ahead;

          while (ahead <= DAC_RING_LEN - 2 * n &&
                 freedv_chain_modem_avail48() >= (int)n)
          {
            uint32_t t0 = DWT->CYCCNT;
            freedv_tx_produce(&dac_buffer[dac_wr], n);
            usb_audio_mic_tx_update(NULL, n);  // FreeDV TX has no sidetone-like monitor buffer
            uint32_t dt = DWT->CYCCNT - t0;
            if (dt > rx_cycles_max)     rx_cycles_max     = dt;
            if (dt > rx_fdv_cycles_max) rx_fdv_cycles_max = dt;

            dac_wr = (dac_wr + n) % DAC_RING_LEN;
            ahead += n;
          }
        }
      }
      else if (dac_block_processing == 1)
      {
          tx_process_block(usb_audio_tx_source(&adc_buffer[0], n), &dac_buffer[0], &sidetone_buffer[0], n);
          usb_audio_mic_tx_update(&sidetone_buffer[0], n);
          dac_block_processing = 0;
      }
      else if (dac_block_processing == 2)
      {
          tx_process_block(usb_audio_tx_source(&adc_buffer[n], n), &dac_buffer[n], &sidetone_buffer[n], n);
          usb_audio_mic_tx_update(&sidetone_buffer[n], n);
          dac_block_processing = 0;
      }
    }
    else
    // RX path. Swap this with the nbfm_tx_process_block() block below to go
    // back to transmit testing.
    if (mode_is_buffered(MODE))
    {
      /*
       * Drain the ADC ring as fast as it fills rather than once per DMA
       * deadline, so a slow frame is caught up on afterwards instead of
       * leaving a backlog that grows until the ring overruns. Output
       * alternates between the two DAC halves - but unlike the deep ADC
       * ring, the RX DAC buffer is only block_size deep (audio_dma_start()
       * only gives TX the deep ring), so a catch-up burst here has nowhere
       * to write ahead into. Without checking where the DMA actually is,
       * a burst of 2+ blocks in one pass can overwrite a half the DMA is
       * still playing, audible as a skip/repeat - this is what the TX path
       * above already guards against via dac_dma_pos(), just missing here.
       */
      static int dac_half = 0;
      uint32_t n = block_size / 2;
      int      guard = 4;   /* keep the loop from starving the telemetry */

      /* Writer lapped us: data was lost, so resync rather than read garbage. */
      if (adc_avail() > ADC_RING_LEN - n)
      {
        rx_overruns++;
        adc_rd = (adc_dma_pos() / n * n) % ADC_RING_LEN;
      }

      while (adc_avail() >= n && guard--)
      {
        /* Only safe to (re)write a half once the DMA has moved into the
           other one - i.e. finished playing this one. If not, stop for now
           and let the deep ADC ring hold the backlog instead; we'll catch
           up next pass once real-time playback has made room.
           Not dac_dma_pos() here - that one measures against DAC_RING_LEN,
           the deep ring TX buffered mode uses, but RX's DAC DMA is only
           block_size long (see audio_dma_start()), so it needs its own
           position calculation against the length it was actually started
           with. */
        uint32_t play = block_size - __HAL_DMA_GET_COUNTER(hdac.DMA_Handle1);
        int dac_half_free = dac_half ? (play < n) : (play >= n);
        if (!dac_half_free)
          break;

        process_block(&adc_buffer[adc_rd], &dac_buffer[dac_half ? n : 0], n);
        usb_audio_rx_capture(&dac_buffer[dac_half ? n : 0], n);
        adc_rd = (adc_rd + n) % ADC_RING_LEN;
        dac_half ^= 1;
      }
    }
    else if (block_ready == 1)
    {
      process_block(&adc_buffer[0], &dac_buffer[0], block_size/2);
      usb_audio_rx_capture(&dac_buffer[0], block_size/2);
      block_ready = 0;
    }
    else if (block_ready == 2)
    {
      process_block(&adc_buffer[block_size/2], &dac_buffer[block_size/2], block_size/2);
      usb_audio_rx_capture(&dac_buffer[block_size/2], block_size/2);
      block_ready = 0;
    }

    // Once a second: are blocks flowing, is there signal, has the modem synced?
    // Only when the continuous debug print is enabled -- off by default so the
    // console prompt stays clean. Toggle with the 'debug' command.
    if (debug_on && HAL_GetTick() - last_report >= 1000)
    {
        last_report = HAL_GetTick();

        // Derived from the active block size so it stays correct across a
        // mode change: at 48 kHz there are 48 samples per millisecond, and the
        // core runs at 216 MHz.
        // In microseconds, not milliseconds: an analog block is 5.33 ms, and
        // rounding that to 5 would overstate the load by 6 %.
        const uint32_t block_us     = (block_size / 2) * 1000u / 48u;
        const uint32_t block_cycles = 216u * block_us;
        uint32_t load_pct = (uint32_t)(((uint64_t)rx_cycles_max * 100u) / block_cycles);

        uart_kv("mode", MODE);
        uart_kv("blocks", (int)rx_blocks);
        uart_kv("ovr", (int)rx_overruns);
        uart_kv("ring", mode_is_buffered(MODE) ? (int)adc_avail() : 0);
        uart_kv("load_pct", (int)load_pct);
        uart_kv("us_max", (int)(rx_cycles_max / 216));
        uart_kv("us_fdv", (int)(rx_fdv_cycles_max / 216));
        uart_kv("us_enc", (int)(rx_adc_cycles / 216));
        uart_kv("cush_us", (int)(tx_cushion_min / 48));
        rx_adc_cycles = 0;
        tx_cushion_min = 999999;
        {
            extern volatile unsigned freedv_tx_underruns;
            uart_kv("txun", (int)freedv_tx_underruns);
            freedv_tx_underruns = 0;
        }
        uart_kv("adc_x1000", (int)(rx_adc_peak * 1000.0f));
        uart_kv("peak_x1000", (int)(rx_peak * 1000.0f));
        uart_kv("rms_x1000", (int)(rx_rms * 1000.0f));
        uart_kv("usb_mic_calls", (int)usb_mic_calls);
        uart_kv("usb_mic_peak_x1000", (int)(usb_mic_peak * 1000.0f));
        usb_mic_calls = 0;
        usb_mic_peak  = 0.0f;
        {
            extern volatile uint32_t usb_mic_underruns, usb_mic_fade_ins, usb_mic_fade_outs;
            uart_kv("usb_mic_under", (int)usb_mic_underruns);
            uart_kv("usb_mic_fadein", (int)usb_mic_fade_ins);
            uart_kv("usb_mic_fadeout", (int)usb_mic_fade_outs);
            usb_mic_underruns  = 0;
            usb_mic_fade_ins   = 0;
            usb_mic_fade_outs  = 0;
        }
        {
            extern volatile uint32_t usb_spk_calls, usb_spk_underruns, usb_spk_avail, usb_spk_avail_min, usb_spk_rx_pkts, usb_spk_nonzero_pkts, usb_spk_laps;
            extern volatile uint32_t usb_setcur_count, usb_setcur_last_unit, usb_setcur_last_value;
            uart_kv("usb_spk_pkts", (int)usb_spk_rx_pkts);
            uart_kv("usb_spk_nz", (int)usb_spk_nonzero_pkts);
            uart_kv("usb_spk_calls", (int)usb_spk_calls);
            uart_kv("usb_spk_under", (int)usb_spk_underruns);
            uart_kv("usb_spk_avail", (int)usb_spk_avail);
            uart_kv("usb_spk_avail_min", (int)usb_spk_avail_min);
            uart_kv("usb_spk_laps", (int)usb_spk_laps);
            uart_kv("usb_setcur_n", (int)usb_setcur_count);
            uart_kv("usb_setcur_unit", (int)usb_setcur_last_unit);
            uart_kv("usb_setcur_val", (int)usb_setcur_last_value);
            usb_spk_rx_pkts      = 0;
            usb_spk_nonzero_pkts = 0;
            usb_spk_calls        = 0;
            usb_spk_underruns    = 0;
            usb_spk_avail_min    = 0xFFFFFFFFU;
            usb_spk_laps         = 0;
        }
        if (MODE == MODE_AM)
        {
            uart_kv("env_min_x1000", (int)(rx_env_min * 1000.0f));
            uart_kv("env_avg_x1000", (int)(rx_env_avg * 1000.0f));
        }
        uart_kv("sync", freedv_chain_synced());
        uart_kv("snr_x10", (int)(freedv_chain_snr() * 10.0f));
        uart_puts("\r\n");

        rx_blocks     = 0;
        rx_overruns   = 0;
        rx_cycles_max = 0;
        rx_fdv_cycles_max = 0;
    }
    /*
    if(dac_block_processing == 1)
    {
        nbfm_tx_process_block(&adc_buffer[0], &dac_buffer[0], block_size/2);
        dac_block_processing = 0;
    }
    else if(dac_block_processing == 2)
    {
        nbfm_tx_process_block(&adc_buffer[block_size/2], &dac_buffer[block_size/2], block_size/2);
        dac_block_processing = 0;
    }
*/

    /* USER CODE END WHILE */

  }
}

void SystemClock_Config(void)
{
  RCC_OscInitTypeDef RCC_OscInitStruct = {0};
  RCC_ClkInitTypeDef RCC_ClkInitStruct = {0};

  /** Configure LSE Drive Capability
  */
  HAL_PWR_EnableBkUpAccess();

  /** Configure the main internal regulator output voltage
  */
  __HAL_RCC_PWR_CLK_ENABLE();
  __HAL_PWR_VOLTAGESCALING_CONFIG(PWR_REGULATOR_VOLTAGE_SCALE1);

  /** Initializes the RCC Oscillators according to the specified parameters
  * in the RCC_OscInitTypeDef structure.
  */
  RCC_OscInitStruct.OscillatorType = RCC_OSCILLATORTYPE_HSE;
  RCC_OscInitStruct.HSEState = RCC_HSE_ON;
  RCC_OscInitStruct.PLL.PLLState = RCC_PLL_ON;
  RCC_OscInitStruct.PLL.PLLSource = RCC_PLLSOURCE_HSE;
  RCC_OscInitStruct.PLL.PLLM = 4;
  RCC_OscInitStruct.PLL.PLLN = 216;
  RCC_OscInitStruct.PLL.PLLP = RCC_PLLP_DIV2;
  RCC_OscInitStruct.PLL.PLLQ = 3;
  if (HAL_RCC_OscConfig(&RCC_OscInitStruct) != HAL_OK)
  {
    Error_Handler();
  }

  /** Activate the Over-Drive mode
  */
  if (HAL_PWREx_EnableOverDrive() != HAL_OK)
  {
    Error_Handler();
  }

  /** Initializes the CPU, AHB and APB buses clocks
  */
  RCC_ClkInitStruct.ClockType = RCC_CLOCKTYPE_HCLK|RCC_CLOCKTYPE_SYSCLK
                              |RCC_CLOCKTYPE_PCLK1|RCC_CLOCKTYPE_PCLK2;
  RCC_ClkInitStruct.SYSCLKSource = RCC_SYSCLKSOURCE_PLLCLK;
  RCC_ClkInitStruct.AHBCLKDivider = RCC_SYSCLK_DIV1;
  RCC_ClkInitStruct.APB1CLKDivider = RCC_HCLK_DIV4;
  RCC_ClkInitStruct.APB2CLKDivider = RCC_HCLK_DIV2;

  if (HAL_RCC_ClockConfig(&RCC_ClkInitStruct, FLASH_LATENCY_7) != HAL_OK)
  {
    Error_Handler();
  }
}

static void MX_ADC1_Init(void)
{

  ADC_ChannelConfTypeDef sConfig = {0};

  /** Configure the global features of the ADC (Clock, Resolution, Data Alignment and number of conversion)
  */
  hadc1.Instance = ADC1;
  hadc1.Init.ClockPrescaler = ADC_CLOCK_SYNC_PCLK_DIV4;
  hadc1.Init.Resolution = ADC_RESOLUTION_12B;
  hadc1.Init.ScanConvMode = ADC_SCAN_DISABLE;
  hadc1.Init.ContinuousConvMode = DISABLE;
  hadc1.Init.DiscontinuousConvMode = DISABLE;
  hadc1.Init.ExternalTrigConvEdge = ADC_EXTERNALTRIGCONVEDGE_RISING;
  hadc1.Init.ExternalTrigConv = ADC_EXTERNALTRIGCONV_T6_TRGO;
  hadc1.Init.DataAlign = ADC_DATAALIGN_RIGHT;
  hadc1.Init.NbrOfConversion = 1;
  hadc1.Init.DMAContinuousRequests = ENABLE;
  hadc1.Init.EOCSelection = ADC_EOC_SINGLE_CONV;
  if (HAL_ADC_Init(&hadc1) != HAL_OK)
  {
    Error_Handler();
  }

  /** Configure for the selected ADC regular channel its corresponding rank in the sequencer and its sample time.
  * RX IF in, PC0 (ADC123_IN10). Was PA3/channel 3 when this ADC also stood
  * in for the mic; the mic moved to ADC2 below so the two directions no
  * longer share a channel.
  */
  sConfig.Channel = ADC_CHANNEL_10;
  sConfig.Rank = ADC_REGULAR_RANK_1;
  sConfig.SamplingTime = ADC_SAMPLETIME_3CYCLES;
  if (HAL_ADC_ConfigChannel(&hadc1, &sConfig) != HAL_OK)
  {
    Error_Handler();
  }

}

static void MX_ADC2_Init(void)
{
  ADC_ChannelConfTypeDef sConfig = {0};

  hadc2.Instance = ADC2;
  hadc2.Init.ClockPrescaler = ADC_CLOCK_SYNC_PCLK_DIV4;
  hadc2.Init.Resolution = ADC_RESOLUTION_12B;
  hadc2.Init.ScanConvMode = ADC_SCAN_DISABLE;
  hadc2.Init.ContinuousConvMode = DISABLE;
  hadc2.Init.DiscontinuousConvMode = DISABLE;
  hadc2.Init.ExternalTrigConvEdge = ADC_EXTERNALTRIGCONVEDGE_RISING;
  hadc2.Init.ExternalTrigConv = ADC_EXTERNALTRIGCONV_T6_TRGO;
  hadc2.Init.DataAlign = ADC_DATAALIGN_RIGHT;
  hadc2.Init.NbrOfConversion = 1;
  hadc2.Init.DMAContinuousRequests = ENABLE;
  hadc2.Init.EOCSelection = ADC_EOC_SINGLE_CONV;
  if (HAL_ADC_Init(&hadc2) != HAL_OK)
  {
    Error_Handler();
  }

  sConfig.Channel = ADC_CHANNEL_3;
  sConfig.Rank = ADC_REGULAR_RANK_1;
  sConfig.SamplingTime = ADC_SAMPLETIME_3CYCLES;
  if (HAL_ADC_ConfigChannel(&hadc2, &sConfig) != HAL_OK)
  {
    Error_Handler();
  }
}

static void MX_DAC_Init(void)
{

  DAC_ChannelConfTypeDef sConfig = {0};

  /** DAC Initialization
  */
  hdac.Instance = DAC;
  if (HAL_DAC_Init(&hdac) != HAL_OK)
  {
    Error_Handler();
  }

  /** DAC channel OUT1 config -- RX audio out, PA4
  */
  sConfig.DAC_Trigger = DAC_TRIGGER_T6_TRGO;
  sConfig.DAC_OutputBuffer = DAC_OUTPUTBUFFER_ENABLE;
  if (HAL_DAC_ConfigChannel(&hdac, &sConfig, DAC_CHANNEL_1) != HAL_OK)
  {
    Error_Handler();
  }

  /** DAC channel OUT2 config -- TX IF out, PA5
  */
  if (HAL_DAC_ConfigChannel(&hdac, &sConfig, DAC_CHANNEL_2) != HAL_OK)
  {
    Error_Handler();
  }

}

static void MX_ETH_Init(void)
{

   static uint8_t MACAddr[6];

  heth.Instance = ETH;
  MACAddr[0] = 0x00;
  MACAddr[1] = 0x80;
  MACAddr[2] = 0xE1;
  MACAddr[3] = 0x00;
  MACAddr[4] = 0x00;
  MACAddr[5] = 0x00;
  heth.Init.MACAddr = &MACAddr[0];
  heth.Init.MediaInterface = HAL_ETH_RMII_MODE;
  heth.Init.TxDesc = DMATxDscrTab;
  heth.Init.RxDesc = DMARxDscrTab;
  heth.Init.RxBuffLen = 1524;

  if (HAL_ETH_Init(&heth) != HAL_OK)
  {
    Error_Handler();
  }

  memset(&TxConfig, 0 , sizeof(ETH_TxPacketConfig));
  TxConfig.Attributes = ETH_TX_PACKETS_FEATURES_CSUM | ETH_TX_PACKETS_FEATURES_CRCPAD;
  TxConfig.ChecksumCtrl = ETH_CHECKSUM_IPHDR_PAYLOAD_INSERT_PHDR_CALC;
  TxConfig.CRCPadCtrl = ETH_CRC_PAD_INSERT;

}

static void MX_I2C1_Init(void)
{

  hi2c1.Instance = I2C1;
  hi2c1.Init.Timing = 0x20404768;
  hi2c1.Init.OwnAddress1 = 0;
  hi2c1.Init.AddressingMode = I2C_ADDRESSINGMODE_7BIT;
  hi2c1.Init.DualAddressMode = I2C_DUALADDRESS_DISABLE;
  hi2c1.Init.OwnAddress2 = 0;
  hi2c1.Init.OwnAddress2Masks = I2C_OA2_NOMASK;
  hi2c1.Init.GeneralCallMode = I2C_GENERALCALL_DISABLE;
  hi2c1.Init.NoStretchMode = I2C_NOSTRETCH_DISABLE;
  if (HAL_I2C_Init(&hi2c1) != HAL_OK)
  {
    Error_Handler();
  }

  /** Configure Analogue filter
  */
  if (HAL_I2CEx_ConfigAnalogFilter(&hi2c1, I2C_ANALOGFILTER_ENABLE) != HAL_OK)
  {
    Error_Handler();
  }

  /** Configure Digital filter
  */
  if (HAL_I2CEx_ConfigDigitalFilter(&hi2c1, 0) != HAL_OK)
  {
    Error_Handler();
  }
  /* USER CODE BEGIN I2C1_Init 2 */

  // Interrupt-driven, not polled: the OLED framebuffer push is ~1 KB, and a
  // blocking transfer at I2C speeds stalls the main loop for tens of ms,
  // which is audible as a glitch in whatever audio block is due during that
  // stall. See oled.c - HAL_I2C_Master_Transmit_IT keeps the loop running.
  // Priority 2 (was 1), 2026-08-05: freed up 1 for USB (see
  // stm32f7xx_hal_msp.c's OTG_FS_IRQn comment) so the ordering stays
  // strictly DMA(0) > USB(1) > I2C1(2), no ties - a cosmetic, rate-capped
  // OLED redraw can afford to lose a race it used to be tied in.
  HAL_NVIC_SetPriority(I2C1_EV_IRQn, 2, 0);
  HAL_NVIC_EnableIRQ(I2C1_EV_IRQn);
  HAL_NVIC_SetPriority(I2C1_ER_IRQn, 2, 0);
  HAL_NVIC_EnableIRQ(I2C1_ER_IRQn);

  /* USER CODE END I2C1_Init 2 */

}

static void MX_TIM6_Init(void)
{

  TIM_MasterConfigTypeDef sMasterConfig = {0};

  htim6.Instance = TIM6;
  htim6.Init.Prescaler = 44;
  htim6.Init.CounterMode = TIM_COUNTERMODE_UP;
  htim6.Init.Period = 49;
  htim6.Init.AutoReloadPreload = TIM_AUTORELOAD_PRELOAD_DISABLE;
  if (HAL_TIM_Base_Init(&htim6) != HAL_OK)
  {
    Error_Handler();
  }
  sMasterConfig.MasterOutputTrigger = TIM_TRGO_UPDATE;
  sMasterConfig.MasterSlaveMode = TIM_MASTERSLAVEMODE_DISABLE;
  if (HAL_TIMEx_MasterConfigSynchronization(&htim6, &sMasterConfig) != HAL_OK)
  {
    Error_Handler();
  }

}

static void MX_USART3_UART_Init(void)
{

  huart3.Instance = USART3;
  huart3.Init.BaudRate = 115200;
  huart3.Init.WordLength = UART_WORDLENGTH_8B;
  huart3.Init.StopBits = UART_STOPBITS_1;
  huart3.Init.Parity = UART_PARITY_NONE;
  huart3.Init.Mode = UART_MODE_TX_RX;
  huart3.Init.HwFlowCtl = UART_HWCONTROL_NONE;
  huart3.Init.OverSampling = UART_OVERSAMPLING_16;
  huart3.Init.OneBitSampling = UART_ONE_BIT_SAMPLE_DISABLE;
  huart3.AdvancedInit.AdvFeatureInit = UART_ADVFEATURE_NO_INIT;
  if (HAL_UART_Init(&huart3) != HAL_OK)
  {
    Error_Handler();
  }

}

static void MX_USB_OTG_FS_PCD_Init(void)
{

  hpcd_USB_OTG_FS.Instance = USB_OTG_FS;
  hpcd_USB_OTG_FS.Init.dev_endpoints = 6;
  hpcd_USB_OTG_FS.Init.speed = PCD_SPEED_FULL;
  /* Second DMA experiment, 2026-08-06 - see git history for the first.
     That one changed two things at once (DMA + multi-packet block
     arming) and failed 100%: USBD_AD_DataOut() never fired at all
     (usb_spk_pkts stuck at 0), most likely because multi-packet
     isochronous DMA transfers on this core don't tolerate a short/
     irregular packet mid-block the way bulk transfers do. This time only
     dma_enable changes - every endpoint still arms exactly one packet at
     a time, the same pattern already proven reliable in slave mode - to
     find out whether DMA transfer itself works on this core at all,
     without also re-testing the multi-packet arming already known to
     fail. If DataIn()/DataOut() don't fire (usb_spk_pkts/usb_mic_calls
     stuck at 0, same signature as before), the answer is no regardless
     of arming granularity, and slave mode is what to keep. */
  hpcd_USB_OTG_FS.Init.dma_enable = ENABLE;
  hpcd_USB_OTG_FS.Init.phy_itface = PCD_PHY_EMBEDDED;
  hpcd_USB_OTG_FS.Init.Sof_enable = ENABLE;
  hpcd_USB_OTG_FS.Init.low_power_enable = DISABLE;
  hpcd_USB_OTG_FS.Init.lpm_enable = DISABLE;
  hpcd_USB_OTG_FS.Init.vbus_sensing_enable = ENABLE;
  hpcd_USB_OTG_FS.Init.use_dedicated_ep1 = DISABLE;
  if (HAL_PCD_Init(&hpcd_USB_OTG_FS) != HAL_OK)
  {
    Error_Handler();
  }

}

static void MX_DMA_Init(void)
{

  /* DMA controller clock enable */
  __HAL_RCC_DMA1_CLK_ENABLE();
  __HAL_RCC_DMA2_CLK_ENABLE();

  /* DMA interrupt init */
  /* DMA1_Stream5_IRQn interrupt configuration */
  HAL_NVIC_SetPriority(DMA1_Stream5_IRQn, 0, 0);
  HAL_NVIC_EnableIRQ(DMA1_Stream5_IRQn);
  /* DMA1_Stream6_IRQn interrupt configuration (DAC channel 2, TX IF out) */
  HAL_NVIC_SetPriority(DMA1_Stream6_IRQn, 0, 0);
  HAL_NVIC_EnableIRQ(DMA1_Stream6_IRQn);
  /* DMA2_Stream0_IRQn interrupt configuration */
  HAL_NVIC_SetPriority(DMA2_Stream0_IRQn, 0, 0);
  HAL_NVIC_EnableIRQ(DMA2_Stream0_IRQn);
  /* DMA2_Stream2_IRQn interrupt configuration (ADC2, TX mic in) */
  HAL_NVIC_SetPriority(DMA2_Stream2_IRQn, 0, 0);
  HAL_NVIC_EnableIRQ(DMA2_Stream2_IRQn);

}

static void MX_GPIO_Init(void)
{
  GPIO_InitTypeDef GPIO_InitStruct = {0};

  /* GPIO Ports Clock Enable */
  __HAL_RCC_GPIOC_CLK_ENABLE();
  __HAL_RCC_GPIOH_CLK_ENABLE();
  __HAL_RCC_GPIOA_CLK_ENABLE();
  __HAL_RCC_GPIOB_CLK_ENABLE();
  __HAL_RCC_GPIOD_CLK_ENABLE();
  __HAL_RCC_GPIOG_CLK_ENABLE();

  /*Configure GPIO pin Output Level */
  HAL_GPIO_WritePin(GPIOB, LD1_Pin|LD3_Pin|LD2_Pin, GPIO_PIN_RESET);

  /*Configure GPIO pin Output Level */
  HAL_GPIO_WritePin(USB_PowerSwitchOn_GPIO_Port, USB_PowerSwitchOn_Pin, GPIO_PIN_RESET);

  /*Configure GPIO pin : USER_Btn_Pin */
  GPIO_InitStruct.Pin = USER_Btn_Pin;
  GPIO_InitStruct.Mode = GPIO_MODE_IT_RISING;
  GPIO_InitStruct.Pull = GPIO_NOPULL;
  HAL_GPIO_Init(USER_Btn_GPIO_Port, &GPIO_InitStruct);

  /*Configure GPIO pins : LD1_Pin LD3_Pin LD2_Pin */
  GPIO_InitStruct.Pin = LD1_Pin|LD3_Pin|LD2_Pin;
  GPIO_InitStruct.Mode = GPIO_MODE_OUTPUT_PP;
  GPIO_InitStruct.Pull = GPIO_NOPULL;
  GPIO_InitStruct.Speed = GPIO_SPEED_FREQ_LOW;
  HAL_GPIO_Init(GPIOB, &GPIO_InitStruct);

  /*Configure GPIO pin : USB_PowerSwitchOn_Pin */
  GPIO_InitStruct.Pin = USB_PowerSwitchOn_Pin;
  GPIO_InitStruct.Mode = GPIO_MODE_OUTPUT_PP;
  GPIO_InitStruct.Pull = GPIO_NOPULL;
  GPIO_InitStruct.Speed = GPIO_SPEED_FREQ_LOW;
  HAL_GPIO_Init(USB_PowerSwitchOn_GPIO_Port, &GPIO_InitStruct);

  /*Configure GPIO pin : USB_OverCurrent_Pin */
  GPIO_InitStruct.Pin = USB_OverCurrent_Pin;
  GPIO_InitStruct.Mode = GPIO_MODE_INPUT;
  GPIO_InitStruct.Pull = GPIO_NOPULL;
  HAL_GPIO_Init(USB_OverCurrent_GPIO_Port, &GPIO_InitStruct);

}

 /* MPU Configuration */

void MPU_Config(void)
{
  MPU_Region_InitTypeDef MPU_InitStruct = {0};

  /* Disables the MPU */
  HAL_MPU_Disable();

  /** Initializes and configures the Region and the memory to be protected
  */
  MPU_InitStruct.Enable = MPU_REGION_ENABLE;
  MPU_InitStruct.Number = MPU_REGION_NUMBER0;
  MPU_InitStruct.BaseAddress = 0x0;
  MPU_InitStruct.Size = MPU_REGION_SIZE_4GB;
  MPU_InitStruct.SubRegionDisable = 0x87;
  MPU_InitStruct.TypeExtField = MPU_TEX_LEVEL0;
  MPU_InitStruct.AccessPermission = MPU_REGION_NO_ACCESS;
  MPU_InitStruct.DisableExec = MPU_INSTRUCTION_ACCESS_DISABLE;
  MPU_InitStruct.IsShareable = MPU_ACCESS_SHAREABLE;
  MPU_InitStruct.IsCacheable = MPU_ACCESS_NOT_CACHEABLE;
  MPU_InitStruct.IsBufferable = MPU_ACCESS_NOT_BUFFERABLE;

  HAL_MPU_ConfigRegion(&MPU_InitStruct);
  /* Enables the MPU */
  HAL_MPU_Enable(MPU_PRIVILEGED_DEFAULT);

}

void Error_Handler(void)
{
  __disable_irq();
  while (1)
  {
  }
}
